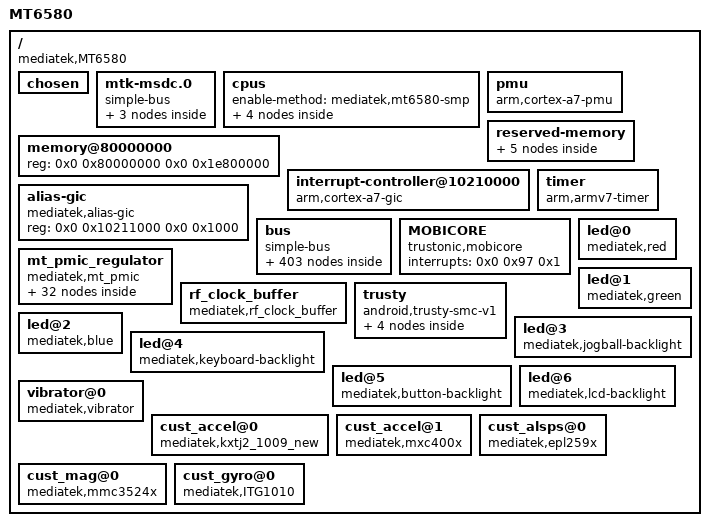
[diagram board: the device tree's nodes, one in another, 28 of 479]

/dts-v1/;

/ {
	model = "MT6580";
	compatible = "mediatek,MT6580";
	interrupt-parent = <0x1>;
	#address-cells = <0x2>;
	#size-cells = <0x2>;

	chosen {
		bootargs = "console=tty0 console=ttyMT0,921600n1 root=/dev/ram initrd=0x84000000,0x400000 loglevel=8";
		atag,videolfb-fb_base = <0x9e800000>;
		atag,videolfb-islcmfound = <0x1>;
		atag,videolfb-fps = <0x1770>;
		atag,videolfb-vramSize = <0x1800000>;
		atag,videolfb-lcmname = "nt35590_AUO";
	};

	mtk-msdc.0 {
		compatible = "simple-bus";
		#address-cells = <0x1>;
		#size-cells = <0x1>;
		ranges = <0x0 0x0 0x0 0xffffffff>;

		msdc0@11120000 {
			compatible = "mediatek,mt6580-mmc";
			reg = <0x11120000 0x10000 0x10001e84 0x2>;
			interrupts = <0x0 0x26 0x8>;
			status = "okay";
			clk_src = [07];
			bus-width = <0x8>;
			max-frequency = <0xc65d400>;
			cap-mmc-highspeed;
			msdc-sys-suspend;
			mmc-hs200-1_8v;
			non-removable;
			pinctl = <0x2>;
			register_setting = <0x3>;
			host_function = [00];
			bootable;
		};

		msdc1@11130000 {
			compatible = "mediatek,mt6580-mmc";
			reg = <0x11130000 0x10000 0x10001e84 0x2>;
			interrupts = <0x0 0x27 0x8>;
			cd-gpios = <0x4 0x3 0x0>;
			status = "okay";
			clk_src = [02];
			bus-width = <0x4>;
			max-frequency = <0xc65d400>;
			msdc-sys-suspend;
			cap-sd-highspeed;
			sd-uhs-sdr12;
			sd-uhs-sdr25;
			sd-uhs-sdr50;
			sd-uhs-sdr104;
			pinctrl-names = "default", "insert_cfg";
			pinctrl-0 = <0x5>;
			pinctrl-1 = <0x6>;
			pinctl = <0x7>;
			pinctl_sdr104 = <0x8>;
			pinctl_sdr50 = <0x9>;
			pinctl_ddr50 = <0xa>;
			register_setting = <0xb>;
			host_function = [01];
			cd_level = [00];
			non-removable;
		};

		default {
			compatible = "mediatek,msdc1_ins-eint";
		};
	};

	cpus {
		#address-cells = <0x1>;
		#size-cells = <0x0>;
		enable-method = "mediatek,mt6580-smp";

		cpu@0 {
			device_type = "cpu";
			compatible = "arm,cortex-a7";
			reg = <0x0>;
			clock-frequency = <0x6553f100>;
		};

		cpu@1 {
			device_type = "cpu";
			compatible = "arm,cortex-a7";
			reg = <0x1>;
			clock-frequency = <0x6553f100>;
		};

		cpu@2 {
			device_type = "cpu";
			compatible = "arm,cortex-a7";
			reg = <0x2>;
			clock-frequency = <0x6553f100>;
		};

		cpu@3 {
			device_type = "cpu";
			compatible = "arm,cortex-a7";
			reg = <0x3>;
			clock-frequency = <0x6553f100>;
		};
	};

	pmu {
		compatible = "arm,cortex-a7-pmu";
		interrupts = <0x0 0x4 0x8 0x0 0x5 0x8 0x0 0x6 0x8 0x0 0x7 0x8>;
	};

	memory@80000000 {
		device_type = "memory";
		reg = <0x0 0x80000000 0x0 0x1e800000>;
	};

	reserved-memory {
		#address-cells = <0x2>;
		#size-cells = <0x2>;
		ranges;

		consys-reserve-memory {
			compatible = "mediatek,consys-reserve-memory";
			no-map;
			size = <0x0 0x200000>;
			alignment = <0x0 0x200000>;
		};

		reserve-memory-ccci_md1 {
			compatible = "mediatek,reserve-memory-ccci_md1";
			no-map;
			size = <0x0 0x1800000>;
			alignment = <0x0 0x2000000>;
			alloc-ranges = <0x0 0x80000000 0x0 0x80000000>;
		};

		pstore-reserved-memory@83f10000 {
			compatible = "mediatek,pstore";
			reg = <0x0 0x83f10000 0x0 0xe0000>;
		};

		ram_console-reserved-memory@83f00000 {
			compatible = "mediatek,ram_console";
			reg = <0x0 0x83f00000 0x0 0x10000>;
		};

		minirdump-reserved-memory@83ff0000 {
			compatible = "mediatek, minirdump";
			reg = <0x0 0x83ff0000 0x0 0x10000>;
		};
	};

	interrupt-controller@10210000 {
		compatible = "arm,cortex-a7-gic";
		#interrupt-cells = <0x3>;
		#address-cells = <0x0>;
		interrupt-controller;
		reg = <0x0 0x10211000 0x0 0x1000 0x0 0x10212000 0x0 0x1000 0x0 0x10200100 0x0 0x1000>;
		interrupts = <0x1 0x9 0xf04>;
		linux,phandle = <0x1>;
		phandle = <0x1>;
	};

	alias-gic {
		compatible = "mediatek,alias-gic";
		reg = <0x0 0x10211000 0x0 0x1000>;
	};

	timer {
		compatible = "arm,armv7-timer";
		interrupts = <0x1 0xd 0x8 0x1 0xe 0x8 0x1 0xb 0x8 0x1 0xa 0x8>;
		clock-frequency = <0xc65d40>;
	};

	bus {
		compatible = "simple-bus";
		#address-cells = <0x1>;
		#size-cells = <0x1>;
		ranges = <0x0 0x0 0x0 0xffffffff>;

		chipid@08000000 {
			compatible = "mediatek,chipid";
			reg = <0x8000000 0x4 0x8000004 0x4 0x8000008 0x4 0x800000c 0x4>;
		};

		TOPCKGEN@0x10000000 {
			compatible = "mediatek,TOPCKGEN";
			reg = <0x10000000 0x1000>;
		};

		INFRACFG_AO@0x10001000 {
			compatible = "mediatek,INFRACFG_AO";
			reg = <0x10001000 0x1000>;
		};

		bat_meter {
			compatible = "mediatek,bat_meter";
			r_bat_sense = <0x4>;
			r_i_sense = <0x4>;
			r_charger_1 = <0x14a>;
			r_charger_2 = <0x27>;
			temperature_t0 = <0x6e>;
			temperature_t1 = <0x0>;
			temperature_t2 = <0x19>;
			temperature_t3 = <0x32>;
			temperature_t = <0xff>;
			fg_meter_resistance = <0x0>;
			q_max_pos_50 = <0xc5d>;
			q_max_pos_25 = <0xc06>;
			q_max_pos_0 = <0xa97>;
			q_max_neg_10 = <0x9de>;
			q_max_pos_50_h_current = <0xc4d>;
			q_max_pos_25_h_current = <0xc07>;
			q_max_pos_0_h_current = <0xa4b>;
			q_max_neg_10_h_current = <0x679>;
			oam_d5 = <0x0>;
			change_tracking_point = <0x1>;
			cust_tracking_point = <0x1>;
			cust_r_sense = <0xdc>;
			cust_hw_cc = <0x0>;
			aging_tuning_value = <0x67>;
			cust_r_fg_offset = <0x0>;
			ocv_board_compesate = <0x0>;
			r_fg_board_base = <0x3e8>;
			r_fg_board_slope = <0x3e8>;
			car_tune_value = <0x64>;
			current_detect_r_fg = <0xa>;
			minerroroffset = <0x3e8>;
			fg_vbat_average_size = <0x12>;
			r_fg_value = <0xa>;
			cust_poweron_delta_capacity_tolrance = <0x1e>;
			cust_poweron_low_capacity_tolrance = <0x5>;
			cust_poweron_max_vbat_tolrance = <0x5a>;
			cust_poweron_delta_vbat_tolrance = <0x1e>;
			cust_poweron_delta_hw_sw_ocv_capacity_tolrance = <0xa>;
			fixed_tbat_25 = <0x0>;
			vbat_normal_wakeup = <0xe10>;
			vbat_low_power_wakeup = <0xdac>;
			normal_wakeup_period = <0x1518>;
			low_power_wakeup_period = <0x12c>;
			close_poweroff_wakeup_period = <0x1e>;
			rbat_pull_up_r = <0x4204>;
			rbat_pull_up_volt = <0x708>;
			batt_temperature_table_num = <0x11>;
			batt_temperature_table = <0xffffffec 0x10a8d 0xfffffff1 0xd192 0xfffffff6 0xa60a 0xfffffffb 0x8464 0x0 0x6a53 0x5 0x5605 0xa 0x4606 0xf 0x3952 0x14 0x2f31 0x19 0x2710 0x1e 0x207b 0x23 0x1b24 0x28 0x16ca 0x2d 0x1335 0x32 0x1041 0x37 0xdcf 0x3c 0xbc6>;
			battery_profile_t0_num = <0x40>;
			battery_profile_t0 = <0x0 0x10ef 0x2 0x10d9 0x4 0x10c5 0x6 0x10b0 0x8 0x109f 0xa 0x108c 0xc 0x107a 0xe 0x1068 0x10 0x105a 0x12 0x1050 0x14 0x1040 0x16 0x1021 0x18 0x1000 0x1a 0xfe3 0x1c 0xfc1 0x1e 0xf8b 0x20 0xf72 0x22 0xf5f 0x24 0xf4e 0x26 0xf41 0x28 0xf35 0x2a 0xf28 0x2c 0xf1e 0x2e 0xf15 0x30 0xf0d 0x31 0xf04 0x33 0xefb 0x35 0xef4 0x37 0xeec 0x39 0xee2 0x3b 0xedc 0x3d 0xed4 0x3f 0xecd 0x41 0xec6 0x43 0xec0 0x45 0xebb 0x47 0xeb6 0x49 0xeb0 0x4b 0xeab 0x4d 0xea4 0x4f 0xe9d 0x51 0xe96 0x53 0xe8f 0x55 0xe86 0x57 0xe7c 0x59 0xe72 0x5b 0xe64 0x5d 0xe4c 0x5f 0xe28 0x61 0xdee 0x63 0xd81 0x64 0xd48 0x64 0xd48 0x64 0xd48 0x64 0xd48 0x64 0xd48 0x64 0xd48 0x64 0xd48 0x64 0xd48 0x64 0xd48 0x64 0xd48 0x64 0xd48 0x64 0xd48 0x64 0xd48>;
			battery_profile_t1_num = <0x40>;
			battery_profile_t1 = <0x0 0x10e9 0x2 0x10cf 0x4 0x10b8 0x6 0x10a4 0x7 0x1091 0x9 0x107f 0xb 0x106d 0xd 0x105a 0xf 0x104a 0x11 0x1038 0x12 0x1027 0x14 0x1016 0x16 0x1006 0x18 0xffa 0x1a 0xfec 0x1c 0xfd5 0x1e 0xfb7 0x1f 0xf9c 0x21 0xf87 0x23 0xf77 0x25 0xf6b 0x27 0xf5e 0x29 0xf51 0x2a 0xf46 0x2c 0xf3c 0x2e 0xf31 0x30 0xf28 0x32 0xf1e 0x34 0xf15 0x35 0xf0c 0x37 0xf05 0x39 0xefd 0x3b 0xef7 0x3d 0xef0 0x3f 0xee8 0x41 0xee1 0x42 0xedb 0x44 0xed4 0x46 0xecd 0x48 0xec6 0x4a 0xebf 0x4c 0xeb8 0x4d 0xeaf 0x4f 0xea7 0x51 0xe9c 0x53 0xe92 0x55 0xe89 0x57 0xe84 0x59 0xe80 0x5a 0xe7d 0x5c 0xe77 0x5e 0xe67 0x60 0xe3d 0x62 0xdf1 0x64 0xd48 0x64 0xd48 0x64 0xd48 0x64 0xd48 0x64 0xd48 0x64 0xd48 0x64 0xd48 0x64 0xd48 0x64 0xd48 0x64 0xd48>;
			battery_profile_t2_num = <0x40>;
			battery_profile_t2 = <0x0 0x10fe 0x2 0x10e9 0x3 0x10d5 0x5 0x10c3 0x6 0x10b1 0x8 0x109e 0xa 0x108c 0xb 0x107a 0xd 0x1069 0xf 0x1057 0x10 0x1046 0x12 0x1035 0x13 0x1024 0x15 0x1013 0x17 0x1003 0x18 0xff5 0x1a 0xfeb 0x1c 0xfd9 0x1d 0xfc4 0x1f 0xfb0 0x20 0xfa4 0x22 0xf99 0x24 0xf8f 0x25 0xf83 0x27 0xf77 0x29 0xf66 0x2a 0xf51 0x2c 0xf3e 0x2d 0xf31 0x2f 0xf26 0x31 0xf1c 0x32 0xf14 0x34 0xf0c 0x36 0xf04 0x37 0xefd 0x39 0xef6 0x3a 0xeef 0x3c 0xee9 0x3e 0xee4 0x3f 0xedf 0x41 0xedb 0x43 0xed7 0x44 0xed2 0x46 0xecd 0x47 0xec8 0x49 0xec3 0x4b 0xebd 0x4c 0xeb7 0x4e 0xeb0 0x50 0xeaa 0x51 0xea5 0x53 0xe9d 0x54 0xe92 0x56 0xe89 0x58 0xe79 0x59 0xe74 0x5b 0xe71 0x5d 0xe70 0x5e 0xe6d 0x60 0xe65 0x61 0xe34 0x63 0xdda 0x64 0xd48 0x64 0xd48>;
			battery_profile_t3_num = <0x40>;
			battery_profile_t3 = <0x0 0x1101 0x2 0x10ed 0x3 0x10dc 0x5 0x10c8 0x6 0x10b5 0x8 0x10a3 0x9 0x1092 0xb 0x107f 0xd 0x106d 0xe 0x105c 0x10 0x104a 0x11 0x1038 0x13 0x1028 0x15 0x1017 0x16 0x1008 0x18 0xff9 0x19 0xfe9 0x1b 0xfd9 0x1c 0xfcb 0x1e 0xfbc 0x20 0xfad 0x21 0xfa1 0x23 0xf94 0x24 0xf88 0x26 0xf7c 0x27 0xf71 0x29 0xf64 0x2b 0xf58 0x2c 0xf43 0x2e 0xf2f 0x2f 0xf22 0x31 0xf18 0x33 0xf0f 0x34 0xf07 0x36 0xeff 0x37 0xef8 0x39 0xef0 0x3a 0xeeb 0x3c 0xee4 0x3e 0xedf 0x3f 0xeda 0x41 0xed5 0x42 0xed1 0x44 0xecd 0x46 0xec8 0x47 0xec3 0x49 0xeb8 0x4a 0xeb0 0x4c 0xeab 0x4d 0xea2 0x4f 0xe9d 0x51 0xe97 0x52 0xe91 0x54 0xe89 0x55 0xe7d 0x57 0xe72 0x58 0xe65 0x5a 0xe61 0x5c 0xe61 0x5d 0xe5f 0x5f 0xe59 0x60 0xe38 0x62 0xdeb 0x64 0xd48>;
			r_profile_t0_num = <0x40>;
			r_profile_t0 = <0x10c 0x10ef 0x138 0x10d9 0x141 0x10c5 0x144 0x10b0 0x151 0x109f 0x14f 0x108c 0x159 0x107a 0x15a 0x1068 0x161 0x105a 0x176 0x1050 0x189 0x1040 0x187 0x1021 0x19b 0x1000 0x1c9 0xfe3 0x247 0xfc1 0x37b 0xf8b 0x3a8 0xf72 0x3a3 0xf5f 0x39b 0xf4e 0x39a 0xf41 0x397 0xf35 0x393 0xf28 0x397 0xf1e 0x398 0xf15 0x39c 0xf0d 0x3a0 0xf04 0x39f 0xefb 0x3a6 0xef4 0x3ab 0xeec 0x3a7 0xee2 0x3af 0xedc 0x3af 0xed4 0x3b7 0xecd 0x3b8 0xec6 0x3bc 0xec0 0x3bf 0xebb 0x3c6 0xeb6 0x3d1 0xeb0 0x3d9 0xeab 0x3e6 0xea4 0x3f2 0xe9d 0x405 0xe96 0x41a 0xe8f 0x42e 0xe86 0x449 0xe7c 0x46d 0xe72 0x48f 0xe64 0x4c0 0xe4c 0x4f8 0xe28 0x54c 0xdee 0x5db 0xd81 0x5db 0xd48 0x5db 0xd48 0x5db 0xd48 0x5db 0xd48 0x5db 0xd48 0x5db 0xd48 0x5db 0xd48 0x5db 0xd48 0x5db 0xd48 0x5db 0xd48 0x5db 0xd48 0x5db 0xd48 0x5db 0xd48>;
			r_profile_t1_num = <0x40>;
			r_profile_t1 = <0xe1 0x10e9 0x17c 0x10cf 0x180 0x10b8 0x182 0x10a4 0x184 0x1091 0x188 0x107f 0x18a 0x106d 0x189 0x105a 0x18f 0x104a 0x190 0x1038 0x196 0x1027 0x195 0x1016 0x195 0x1006 0x19c 0xffa 0x1a3 0xfec 0x19c 0xfd5 0x198 0xfb7 0x192 0xf9c 0x186 0xf87 0x183 0xf77 0x183 0xf6b 0x17b 0xf5e 0x173 0xf51 0x173 0xf46 0x176 0xf3c 0x173 0xf31 0x176 0xf28 0x174 0xf1e 0x176 0xf15 0x176 0xf0c 0x17b 0xf05 0x17b 0xefd 0x181 0xef7 0x182 0xef0 0x180 0xee8 0x182 0xee1 0x18a 0xedb 0x184 0xed4 0x186 0xecd 0x188 0xec6 0x184 0xebf 0x184 0xeb8 0x17f 0xeaf 0x181 0xea7 0x181 0xe9c 0x17c 0xe92 0x179 0xe89 0x17d 0xe84 0x185 0xe80 0x196 0xe7d 0x1b0 0xe77 0x1c6 0xe67 0x1d0 0xe3d 0x1e6 0xdf1 0x1e6 0xd48 0x1e6 0xd48 0x1e6 0xd48 0x1e6 0xd48 0x1e6 0xd48 0x1e6 0xd48 0x1e6 0xd48 0x1e6 0xd48 0x1e6 0xd48 0x1e6 0xd48>;
			r_profile_t2_num = <0x40>;
			r_profile_t2 = <0x8a 0x10fe 0x57 0x10e9 0x58 0x10d5 0x5c 0x10c3 0x5c 0x10b1 0x5c 0x109e 0x5d 0x108c 0x5e 0x107a 0x63 0x1069 0x65 0x1057 0x66 0x1046 0x66 0x1035 0x66 0x1024 0x65 0x1013 0x6a 0x1003 0x69 0xff5 0x70 0xfeb 0x6e 0xfd9 0x71 0xfc4 0x72 0xfb0 0x7b 0xfa4 0x7e 0xf99 0x81 0xf8f 0x86 0xf83 0x85 0xf77 0x7e 0xf66 0x70 0xf51 0x64 0xf3e 0x5d 0xf31 0x5e 0xf26 0x5f 0xf1c 0x5f 0xf14 0x5f 0xf0c 0x5e 0xf04 0x5e 0xefd 0x5c 0xef6 0x5c 0xeef 0x5e 0xee9 0x5b 0xee4 0x5f 0xedf 0x62 0xedb 0x65 0xed7 0x63 0xed2 0x62 0xecd 0x62 0xec8 0x5e 0xec3 0x5d 0xebd 0x5e 0xeb7 0x5b 0xeb0 0x5b 0xeaa 0x60 0xea5 0x5e 0xe9d 0x60 0xe92 0x64 0xe89 0x5b 0xe79 0x5b 0xe74 0x5f 0xe71 0x66 0xe70 0x6e 0xe6d 0x79 0xe65 0x6e 0xe34 0x7a 0xdda 0x7a 0xd48 0x7a 0xd48>;
			r_profile_t3_num = <0x40>;
			r_profile_t3 = <0x6e 0x1101 0x35 0x10ed 0x3a 0x10dc 0x38 0x10c8 0x39 0x10b5 0x3a 0x10a3 0x3c 0x1092 0x3b 0x107f 0x39 0x106d 0x3d 0x105c 0x3b 0x104a 0x3a 0x1038 0x3b 0x1028 0x3a 0x1017 0x3e 0x1008 0x3e 0xff9 0x3d 0xfe9 0x3c 0xfd9 0x43 0xfcb 0x43 0xfbc 0x40 0xfad 0x42 0xfa1 0x45 0xf94 0x49 0xf88 0x4d 0xf7c 0x50 0xf71 0x55 0xf64 0x57 0xf58 0x4b 0xf43 0x3f 0xf2f 0x3e 0xf22 0x3c 0xf18 0x3e 0xf0f 0x3b 0xf07 0x40 0xeff 0x3b 0xef8 0x38 0xef0 0x40 0xeeb 0x3d 0xee4 0x40 0xedf 0x41 0xeda 0x40 0xed5 0x44 0xed1 0x44 0xecd 0x46 0xec8 0x48 0xec3 0x3f 0xeb8 0x3f 0xeb0 0x41 0xeab 0x3e 0xea2 0x41 0xe9d 0x3f 0xe97 0x40 0xe91 0x41 0xe89 0x41 0xe7d 0x41 0xe72 0x3c 0xe65 0x3b 0xe61 0x41 0xe61 0x45 0xe5f 0x4d 0xe59 0x47 0xe38 0x51 0xdeb 0x51 0xd48>;
		};

		BAT_NOTIFY {
			compatible = "mediatek,bat_notify";
		};

		bat_comm {
			compatible = "mediatek,battery";
			stop_charging_in_takling = <0x1>;
			talking_recharge_voltage = <0xed8>;
			talking_sync_time = <0x3c>;
			mtk_temperature_recharge_support = <0x1>;
			max_charge_temperature = <0x32>;
			max_charge_temperature_minus_x_degree = <0x2f>;
			min_charge_temperature = <0x0>;
			min_charge_temperature_plus_x_degree = <0x6>;
			err_charge_temperature = <0xff>;
			v_pre2cc_thres = <0xd48>;
			v_cc2topoff_thres = <0x10cc>;
			recharging_voltage = <0x10a4>;
			charging_full_current = <0xb4>;
			config_usb_if = <0x0>;
			usb_charger_current_suspend = <0x0>;
			usb_charger_current_unconfigured = <0x1b58>;
			usb_charger_current_configured = <0xc350>;
			usb_charger_current = <0xc350>;
			ac_charger_current = <0x1adb0>;
			non_std_ac_charger_current = <0xc350>;
			charging_host_charger_current = <0xfde8>;
			apple_0_5a_charger_current = <0xc350>;
			apple_1_0a_charger_current = <0xfde8>;
			apple_2_1a_charger_current = <0x13880>;
			bat_low_temp_protect_enable = <0x0>;
			v_charger_enable = <0x0>;
			v_charger_max = <0x1964>;
			v_charger_min = <0x1130>;
			onehundred_percent_tracking_time = <0xa>;
			npercent_tracking_time = <0x14>;
			sync_to_real_tracking_time = <0x3c>;
			v_0percent_tracking = <0xd7a>;
			high_battery_voltage_support = <0x1>;
		};

		keypad@10002000 {
			compatible = "mediatek,mt6580-keypad";
			reg = <0x10002000 0x1000>;
			interrupts = <0x0 0x6d 0x2>;
			mediatek,kpd-key-debounce = <0x400>;
			mediatek,kpd-sw-pwrkey = <0x74>;
			mediatek,kpd-hw-pwrkey = <0x8>;
			mediatek,kpd-sw-rstkey = <0x66>;
			mediatek,kpd-hw-rstkey = <0x11>;
			mediatek,kpd-use-extend-type = <0x0>;
			mediatek,kpd-hw-map-num = <0x48>;
            mediatek,kpd-hw-init-map = <115 114 0 0 0 0 0 0 0 0 
			                    	0 0 0 0 0 0 0 0 0 
					    	    	0 0 0 0 0 0 0 0 0 
							   		0 0 0 0 0 0 0 0 0 
						   			0 0 0 0 0 0 0 0 0 
						   			0 0 0 0 0 0 0 0 0 
							   		0 0 0 0 0 0 0 0 0 
							   		0 0 0 0 0 0 0 0 >;	
			mediatek,kpd-pwrkey-eint-gpio = <0x0>;
			mediatek,kpd-pwkey-gpio-din = <0x0>;
			mediatek,kpd-hw-dl-key0 = <0x0>;
			mediatek,kpd-hw-dl-key1 = <0x1>;
			mediatek,kpd-hw-dl-key2 = <0x8>;
			mediatek,kpd-hw-recovery-key = <0>;
			mediatek,kpd-hw-factory-key = <1>;
			status = "okay";
		};

		PERICFG@0x10003000 {
			compatible = "mediatek,PERICFG";
			reg = <0x10003000 0x1000>;
		};

		RESERVED@0x10004000 {
			compatible = "mediatek,RESERVED";
			reg = <0x10004000 0x1000>;
		};

		gpio {
			compatible = "mediatek,gpio_usage_mapping";
			GPIO_SIM1_SCLK = <0x16>;
			GPIO_SIM1_SIO = <0x17>;
			GPIO_SIM2_SIO = <0x18>;
			GPIO_SIM2_SCLK = <0x19>;
		};

		gpio@0x10005000 {
			compatible = "mediatek,gpio";
			reg = <0x10005000 0x1000>;
		};

		SLEEP@0x10006000 {
			compatible = "mediatek,SLEEP";
			reg = <0x10006000 0x1000>;
			interrupts = <0x0 0x58 0x8 0x0 0x59 0x8 0x0 0x5a 0x8 0x0 0x5b 0x8>;
		};

		TOPRGU@0x10007000 {
			compatible = "mediatek,TOPRGU";
			reg = <0x10007000 0x1000>;
			interrupts = <0x0 0x9d 0x2>;
		};

		APXGPT@0x10008000 {
			compatible = "mediatek,APXGPT";
			reg = <0x10008000 0x1000>;
			interrupts = <0x0 0x5c 0x8>;
			clock-frequency = <0xc65d40>;
		};

		EFUSEC@0x10009000 {
			compatible = "mediatek,EFUSEC";
			reg = <0x10009000 0x1000>;
		};

		hacc@0x1000A000 {
			compatible = "mediatek,hacc";
			reg = <0x1000a000 0x1000>;
			interrupts = <0x0 0x6e 0x0>;
		};

		cpu_dbgapb@10170000 {
			compatible = "mediatek,hw_dbg";
			num = <0x4>;
			reg = <0x10170000 0x2000 0x10172000 0x2000 0x10174000 0x2000 0x10176000 0x2000>;
		};

		eintc@1000b000 {
			compatible = "mediatek,mt-eic";
			reg = <0x1000b000 0x1000>;
			interrupts = <0x0 0x5e 0x4>;
			#interrupt-cells = <0x2>;
			interrupt-controller;
			mediatek,max_eint_num = <0x1a>;
			mediatek,mapping_table_entry = <0x53>;
			mediatek,mapping_table = <0x0 0x0 0x1 0x1 0x2 0x2 0x3 0x3 0x4 0x4 0x5 0x5 0x6 0x6 0x7 0x7 0x8 0x8 0x9 0x9 0xa 0xa 0xb 0xb 0xc 0xc 0xd 0xd 0xe 0xe 0xf 0xf 0x10 0x0 0x11 0x1 0x12 0x2 0x13 0x3 0x14 0x4 0x15 0x5 0x16 0x6 0x17 0x7 0x18 0x8 0x19 0x9 0x1a 0xa 0x1b 0xb 0x1c 0xc 0x1d 0xd 0x1e 0xe 0x1f 0xf 0x20 0x0 0x21 0x1 0x22 0x2 0x23 0x3 0x24 0x4 0x25 0x5 0x26 0x6 0x27 0x7 0x28 0x8 0x29 0x9 0x2a 0xa 0x2b 0xb 0x2c 0xc 0x2d 0xd 0x2e 0xe 0x2f 0xf 0x30 0x0 0x31 0x1 0x32 0x2 0x33 0x3 0x34 0x3 0x35 0x4 0x36 0x5 0x37 0x6 0x38 0x7 0x39 0x8 0x3a 0xa 0x3b 0xb 0x3c 0xc 0x3d 0xd 0x3e 0xe 0x3f 0xf 0x40 0x0 0x41 0x1 0x42 0x2 0x43 0x3 0x44 0x10 0x45 0x4 0x46 0x5 0x47 0x6 0x48 0x7 0x49 0x8 0x4a 0x9 0x4b 0xa 0x4c 0xb 0x4d 0xc 0x4e 0xd 0x51 0x0 0x52 0x1 0x53 0x2 0x54 0x3>;
			mediatek,builtin_entry = <0xb>;
			mediatek,builtin_mapping = <0x0 0x3 0x14 0x1 0x3 0x12 0x7 0x4 0x14 0x8 0x4 0x12 0x9 0x3 0x14 0xa 0x3 0x12 0x18 0x5 0x14 0x19 0x5 0x12 0x4d 0x2 0x14 0x4e 0x2 0x12 0xd 0x1 0x11>;
			linux,phandle = <0xc>;
			phandle = <0xc>;

			pmic@13 {
				compatible = "mediatek, pmic-eint";
				interrupt-parent = <0xc>;
				interrupts = <0xd 0x4>;
				debounce = <0xd 0x3e8>;
			};
		};

		ap_ccif0@1000C000 {
			compatible = "mediatek,ap_ccif0";
			reg = <0x1000c000 0x1000 0x1000d000 0x1000>;
			interrupts = <0x0 0x5d 0x8 0x0 0x98 0x2>;
			mediatek,ccif_capability = <0x2>;
			mediatek,md_smem_size = <0x200000>;
		};

		MCUSYS_CFGREG@0x1020000 {
			compatible = "mediatek,MCUSYS_CFGREG_BASE";
			reg = <0x1020000 0x200>;
		};

		mcucfg@10200000 {
			compatible = "mediatek,mt6580-mcucfg";
			reg = <0x10200000 0x200>;
		};

		AES@0x1000E000 {
			compatible = "mediatek,AES";
			reg = <0x1000e000 0x1000>;
		};

		PWRAP@0x1000F000 {
			compatible = "mediatek,PWRAP";
			reg = <0x1000f000 0x1000>;
			interrupts = <0x0 0x6c 0x0>;
		};

		DEVAPC_AO@0x10010000 {
			compatible = "mediatek,DEVAPC_AO";
			reg = <0x10010000 0x1000>;
		};

		MIPI_CONFG@0x10011000 {
			compatible = "mediatek,MIPI_CONFG";
			reg = <0x10011000 0x1000>;
		};

		INFRA_MBIST@0x10012000 {
			compatible = "mediatek,INFRA_MBIST";
			reg = <0x10012000 0x1000>;
		};

		RESERVED@0x10013000 {
			compatible = "mediatek,RESERVED";
			reg = <0x10013000 0x1000>;
		};

		IOCFG_T@0x10014000 {
			compatible = "mediatek,IOCFG_T";
			reg = <0x10014000 0x1000>;
		};

		IOCFG_B@0x10015000 {
			compatible = "mediatek,IOCFG_B";
			reg = <0x10015000 0x1000>;
		};

		IOCFG_L@0x10016000 {
			compatible = "mediatek,IOCFG_L";
			reg = <0x10016000 0x1000>;
		};

		IOCFG_R@0x10017000 {
			compatible = "mediatek,IOCFG_R";
			reg = <0x10017000 0x1000>;
		};

		APMIXED@0x10018000 {
			compatible = "mediatek,APMIXED";
			reg = <0x10018000 0x1000>;
		};

		MCUCFG@0x10200000 {
			compatible = "mediatek,MCUCFG";
			reg = <0x10200000 0x1000>;
		};

		INFRACFG@0x10201000 {
			compatible = "mediatek,INFRACFG";
			reg = <0x10201000 0x1000>;
		};

		sys_cirq@10202000 {
			compatible = "mediatek,mt6580-sys_cirq", "mediatek,mt6735-sys_cirq";
			reg = <0x10202000 0x1000>;
			interrupts = <0x0 0x9e 0x8>;
			mediatek,cirq_num = <0x7e>;
			mediatek,spi_start_offset = <0x20>;
		};

		m4u@10203000 {
			cell-index = <0x0>;
			compatible = "mediatek,m4u";
			reg = <0x10203000 0x1000>;
			interrupts = <0x0 0x51 0x8>;
		};

		DEVAPC@0x10204000 {
			compatible = "mediatek,DEVAPC";
			reg = <0x10204000 0x1000>;
			interrupts = <0x0 0x4a 0x8>;
		};

		EMI@0x10205000 {
			compatible = "mediatek,EMI";
			reg = <0x10205000 0x1000>;
			interrupts = <0x0 0x4c 0x4>;
		};

		DRAMC_NAO@0x10206000 {
			compatible = "mediatek,DRAMC_NAO";
			reg = <0x10206000 0x1000>;
		};

		DRAMC0@0x10207000 {
			compatible = "mediatek,DRAMC0";
			reg = <0x10207000 0x1000>;
		};

		DDRPHY@0x10208000 {
			compatible = "mediatek,DDRPHY";
			reg = <0x10208000 0x1000>;
		};

		SRAMROM@0x10209000 {
			compatible = "mediatek,SRAMROM";
			reg = <0x10209000 0x1000>;
		};

		gce@1020a000 {
			compatible = "mediatek,gce";
			reg = <0x1020a000 0x1000>;
			interrupts = <0x0 0x55 0x8 0x0 0x56 0x8>;
			disp_mutex_reg = <0x14015000 0x1000>;
			g3d_config_base = <0x13000000 0x0 0xffff0000>;
			mmsys_config_base = <0x14000000 0x1 0xffff0000>;
			disp_dither_base = <0x14010000 0x2 0xffff0000>;
			mm_na_base = <0x14020000 0x3 0xffff0000>;
			imgsys_base = <0x15000000 0x4 0xffff0000>;
			vdec_gcon_base = <0x16000000 0x5 0xffff0000>;
			venc_gcon_base = <0x17000000 0x6 0xffff0000>;
			conn_peri_base = <0x18000000 0x7 0xffff0000>;
			topckgen_base = <0x10000000 0x8 0xffff0000>;
			kp_base = <0x10010000 0x9 0xffff0000>;
			scp_sram_base = <0x10020000 0xa 0xffff0000>;
			infra_na3_base = <0x10030000 0xb 0xffff0000>;
			infra_na4_base = <0x10040000 0xc 0xffff0000>;
			scp_base = <0x10050000 0xd 0xffff0000>;
			mcucfg_base = <0x10200000 0xe 0xffff0000>;
			gcpu_base = <0x10210000 0xf 0xffff0000>;
			usb0_base = <0x11200000 0x10 0xffff0000>;
			usb_sif_base = <0x11210000 0x11 0xffff0000>;
			audio_base = <0x11220000 0x12 0xffff0000>;
			msdc0_base = <0x11230000 0x13 0xffff0000>;
			msdc1_base = <0x11240000 0x14 0xffff0000>;
			msdc2_base = <0x11250000 0x15 0xffff0000>;
			msdc3_base = <0x11260000 0x16 0xffff0000>;
			pwm_sw_base = <0x1100f000 0x63 0xfffff000>;
			mdp_rdma0_sof = <0x0>;
			mdp_rsz0_sof = <0x1>;
			mdp_rsz1_sof = <0x2>;
			mdp_tdshp_sof = <0x3>;
			mdp_wdma_sof = <0x4>;
			mdp_wrot_sof = <0x5>;
			disp_ovl0_sof = <0x6>;
			disp_rdma0_sof = <0x8>;
			disp_wdma0_sof = <0xa>;
			disp_color_sof = <0xc>;
			disp_aal_sof = <0xd>;
			disp_gamma_sof = <0xe>;
			disp_dither_sof = <0xf>;
			disp_pwm0_sof = <0x11>;
			mdp_rdma0_frame_done = <0x12>;
			mdp_rsz0_frame_done = <0x13>;
			mdp_rsz1_frame_done = <0x14>;
			mdp_tdshp_frame_done = <0x15>;
			mdp_wdma_frame_done = <0x16>;
			mdp_wrot_write_frame_done = <0x17>;
			mdp_wrot_read_frame_done = <0x18>;
			disp_ovl0_frame_done = <0x19>;
			disp_rdma0_frame_done = <0x1b>;
			disp_wdma0_frame_done = <0x1d>;
			disp_color_frame_done = <0x1f>;
			disp_aal_frame_done = <0x20>;
			disp_gamma_frame_done = <0x21>;
			disp_dither_frame_done = <0x22>;
			disp_dsi0_frame_done = <0x25>;
			stream_done_0 = <0x26>;
			stream_done_1 = <0x27>;
			stream_done_2 = <0x28>;
			stream_done_3 = <0x29>;
			stream_done_4 = <0x2a>;
			stream_done_5 = <0x2b>;
			stream_done_6 = <0x2c>;
			stream_done_7 = <0x2d>;
			stream_done_8 = <0x2e>;
			stream_done_9 = <0x2f>;
			buf_underrun_event_0 = <0x30>;
			dsi0_te_event = <0x32>;
			isp_frame_done_p2_1 = <0x42>;
			isp_frame_done_p2_0 = <0x43>;
			seninf_cam0_fifo_full = <0x49>;
			apxgpt2_count = <0x10008028>;
		};

		bus_dbg@1020b000 {
			compatible = "mediatek,bus_dbg-v2";
			reg = <0x1020b000 0x1000>;
			interrupts = <0x0 0x49 0x8>;
			two_stage_timeout = <0x1>;
		};

		TRNG@0x1020C000 {
			compatible = "mediatek,TRNG";
			reg = <0x1020c000 0x1000>;
			interrupts = <0x0 0x57 0x8>;
		};

		MCUCFG_BIU@0x1020D000 {
			compatible = "mediatek,MCUCFG_BIU";
			reg = <0x1020d000 0x1000>;
		};

		DBGSYS_DEM@0x1011A000 {
			compatible = "mediatek,DBGSYS_DEM";
			reg = <0x1011a000 0x1000>;
		};

		DBGSYS_CTI@0x10112000 {
			compatible = "mediatek,DBGSYS_CTI";
			reg = <0x10112000 0x1000>;
		};

		DBGSYS_DAPROM@0x10110000 {
			compatible = "mediatek,DBGSYS_DAPROM";
			reg = <0x10110000 0x1000>;
		};

		DBGSYS_CPU@0x10160000 {
			compatible = "mediatek,DBGSYS_CPU";
			reg = <0x10160000 0x20000>;
		};

		DBGSYS_MDSYS@0x10120000 {
			compatible = "mediatek,DBGSYS_MDSYS";
			reg = <0x10120000 0x10000>;
		};

		dma@0x11000000 {
			compatible = "mediatek,ap_dma";
			reg = <0x11000000 0x1000>;
			interrupts = <0x0 0x30 0x8>;
		};

		NFI@0x11001000 {
			compatible = "mediatek,NFI";
			reg = <0x11001000 0x1000>;
			interrupts = <0x0 0x2f 0x8>;
		};

		NFIECC@0x11002000 {
			compatible = "mediatek,NFIECC";
			reg = <0x11002000 0x1000>;
			interrupts = <0x0 0x2e 0x8>;
		};

		adc_hw@11003000 {
			compatible = "mediatek,mt6735-auxadc";
			reg = <0x11003000 0x1000>;
			interrupts = <0x0 0x23 0x2>;

			adc_channel@ {
				compatible = "mediatek,adc_channel";
				mediatek,temperature0 = <0x0>;
				mediatek,adc_fdd_rf_params_dynamic_custom_ch = <0x1>;
				mediatek,lcm_voltage = <0xc>;
				status = "okay";
			};
		};

		FHCTL@0x11004000 {
			compatible = "mediatek,FHCTL";
			reg = <0x11004000 0x1000>;
		};

		AP_UART0@0x11005000 {
			cell-index = <0x0>;
			compatible = "mediatek,AP_UART0";
			reg = <0x11005000 0x1000>;
			interrupts = <0x0 0x2c 0x8>;
		};

		AP_UART1@0x11006000 {
			cell-index = <0x1>;
			compatible = "mediatek,AP_UART1";
			reg = <0x11006000 0x1000>;
			interrupts = <0x0 0x2d 0x8>;
		};

		AP_DMA_UART0_TX@0x11000480 {
			compatible = "mediatek,AP_DMA_UART0_TX";
			reg = <0x11000480 0x80>;
			interrupts = <0x0 0x38 0x8>;
		};

		AP_DMA_UART0_RX@0x11000500 {
			compatible = "mediatek,AP_DMA_UART0_RX";
			reg = <0x11000500 0x80>;
			interrupts = <0x0 0x39 0x8>;
		};

		AP_DMA_UART1_TX@0x11000580 {
			compatible = "mediatek,AP_DMA_UART1_TX";
			reg = <0x11000580 0x80>;
			interrupts = <0x0 0x3a 0x8>;
		};

		AP_DMA_UART1_RX@0x11000600 {
			compatible = "mediatek,AP_DMA_UART1_RX";
			reg = <0x11000600 0x80>;
			interrupts = <0x0 0x3b 0x8>;
		};

		PWM@0x11008000 {
			compatible = "mediatek,PWM";
			reg = <0x11008000 0x1000>;
			interrupts = <0x0 0x24 0x8>;
		};

		syscfg_pctl_a@0x10005000 {
			compatible = "mediatek,mt6580-pctl-a-syscfg", "syscon";
			reg = <0x10211000 0x1000>;
			linux,phandle = <0xd>;
			phandle = <0xd>;
		};

		pinctrl@0x10005000 {
			compatible = "mediatek,mt6580-pinctrl";
			reg = <0x10005000 0x1000>;
			mediatek,pctl-regmap = <0xd>;
			pins-are-numbered;
			gpio-controller;
			#gpio-cells = <0x2>;
			linux,phandle = <0x4>;
			phandle = <0x4>;

			mmc0@default {
				linux,phandle = <0x2>;
				phandle = <0x2>;

				pins_cmd {
					drive-strength = [02];
				};

				pins_dat {
					drive-strength = [02];
				};

				pins_clk {
					drive-strength = [02];
				};

				pins_rst {
					drive-strength = [02];
				};

				pins_ds {
					drive-strength = [02];
				};
			};

			mmc0@register_default {
				dat0rddly = [00];
				dat1rddly = [00];
				dat2rddly = [00];
				dat3rddly = [00];
				dat4rddly = [00];
				dat5rddly = [00];
				dat6rddly = [00];
				dat7rddly = [00];
				datwrddly = [00];
				cmdrrddly = [00];
				cmdrddly = [00];
				cmd_edge = [01];
				rdata_edge = [01];
				wdata_edge = [01];
				ett-hs200-cells = <0xc>;
				ett-hs200-default = <0xb0 0x380 0x0 0xb0 0x7c00 0x0 0xb4 0x38 0x1 0x4 0x2 0x1 0xf0 0x1f0000 0x0 0xf0 0x7c00000 0x0 0xb4 0x7 0x1 0xf0 0x1f 0x0 0x4 0x100 0x1 0xf8 0x1f000000 0x0 0xf0 0x1f00 0x0 0xb0 0x8 0x1>;
				linux,phandle = <0x3>;
				phandle = <0x3>;
			};

			mmc1@default {
				linux,phandle = <0x7>;
				phandle = <0x7>;

				pins_cmd {
					drive-strength = [03];
				};

				pins_dat {
					drive-strength = [03];
				};

				pins_clk {
					drive-strength = [03];
				};
			};

			mmc1_ins_default {
				linux,phandle = <0x5>;
				phandle = <0x5>;
			};

			mmc1_ins_cfg {
				linux,phandle = <0x6>;
				phandle = <0x6>;

				pins_insert {
					pins = <0x2200>;
					input-schmitt-enable = <0x1>;
					slew-rate = <0x0>;
					bias-pull-up = <0x0>;
				};
			};

			mmc1@sdr104 {
				linux,phandle = <0x8>;
				phandle = <0x8>;

				pins_cmd {
					drive-strength = [02];
				};

				pins_dat {
					drive-strength = [02];
				};

				pins_clk {
					drive-strength = [03];
				};
			};

			mmc1@sdr50 {
				linux,phandle = <0x9>;
				phandle = <0x9>;

				pins_cmd {
					drive-strength = [02];
				};

				pins_dat {
					drive-strength = [02];
				};

				pins_clk {
					drive-strength = [03];
				};
			};

			mmc1@ddr50 {
				linux,phandle = <0xa>;
				phandle = <0xa>;

				pins_cmd {
					drive-strength = [02];
				};

				pins_dat {
					drive-strength = [02];
				};

				pins_clk {
					drive-strength = [03];
				};
			};

			mmc1@register_default {
				dat0rddly = [00];
				dat1rddly = [00];
				dat2rddly = [00];
				dat3rddly = [00];
				datwrddly = [00];
				cmdrrddly = [00];
				cmdrddly = [00];
				cmd_edge = [01];
				rdata_edge = [01];
				wdata_edge = [01];
				linux,phandle = <0xb>;
				phandle = <0xb>;
			};

			alspspincfg {
				linux,phandle = <0x62>;
				phandle = <0x62>;

				pins_cmd_dat {
					pins = <0x1206>;
					slew-rate = <0x0>;
					bias-pull-up = <0x0>;
				};
			};

			alspsdefaultcfg {
				linux,phandle = <0x61>;
				phandle = <0x61>;
			};

			gyropincfg {
				linux,phandle = <0x64>;
				phandle = <0x64>;

				pins_cmd_dat {
					pins = <0x2200>;
					slew-rate = <0x0>;
					bias-pull-down = <0x0>;
				};
			};

			gyrodefaultcfg {
				linux,phandle = <0x63>;
				phandle = <0x63>;
			};

			eint0default {
				linux,phandle = <0x15>;
				phandle = <0x15>;
			};

			eint@0 {
				linux,phandle = <0x16>;
				phandle = <0x16>;

				pins_cmd_dat {
					pins = <0xe06>;
					slew-rate = <0x0>;
					bias-disable;
				};
			};

			toucheint5default {
				linux,phandle = <0xf>;
				phandle = <0xf>;
			};

			toucheint@5 {
				linux,phandle = <0x10>;
				phandle = <0x10>;

				pins_cmd_dat {
					pins = <0x506>;
					slew-rate = <0x0>;
					bias-disable;
				};
			};

			eintoutput0 {
				linux,phandle = <0x11>;
				phandle = <0x11>;

				pins_cmd_dat {
					pins = <0x500>;
					slew-rate = <0x1>;
					output-low;
				};
			};

			eintoutput1 {
				linux,phandle = <0x12>;
				phandle = <0x12>;

				pins_cmd_dat {
					pins = <0x500>;
					slew-rate = <0x1>;
					output-high;
				};
			};

			rstoutput0 {
				linux,phandle = <0x13>;
				phandle = <0x13>;

				pins_cmd_dat {
					pins = <0x600>;
					slew-rate = <0x1>;
					output-low;
				};
			};

			rstoutput1 {
				linux,phandle = <0x14>;
				phandle = <0x14>;

				pins_cmd_dat {
					pins = <0x600>;
					slew-rate = <0x1>;
					output-high;
				};
			};

			audiodefault {
				linux,phandle = <0x3a>;
				phandle = <0x3a>;
			};

			pmicclkmode0 {
				linux,phandle = <0x3b>;
				phandle = <0x3b>;

				pins_cmd0_dat {
					pins = <0x1a00>;
				};

				pins_cmd1_dat {
					pins = <0x1c00>;
				};

				pins_cmd2_dat {
					pins = <0x1b00>;
				};
			};

			pmicclkmode1 {
				linux,phandle = <0x3c>;
				phandle = <0x3c>;

				pins_cmd0_dat {
					pins = <0x1a01>;
				};

				pins_cmd1_dat {
					pins = <0x1c01>;
				};

				pins_cmd2_dat {
					pins = <0x1b01>;
				};
			};

			audexamphigh {
				linux,phandle = <0x3d>;
				phandle = <0x3d>;

				pins_cmd_dat {
					pins = <0x1100>;
					slew-rate = <0x1>;
					output-high;
				};
			};

			audexamplow {
				linux,phandle = <0x3e>;
				phandle = <0x3e>;

				pins_cmd_dat {
					pins = <0x1100>;
					slew-rate = <0x1>;
					output-low;
				};
			};

			audheadsetswhigh {
				linux,phandle = <0x3f>;
				phandle = <0x3f>;

				pins_cmd_dat {
					pins = <0x1100>;
					slew-rate = <0x1>;
					output-high;
				};
			};

			audheadsetswlow {
				linux,phandle = <0x40>;
				phandle = <0x40>;

				pins_cmd_dat {
					pins = <0x1100>;
					slew-rate = <0x1>;
					output-low;
				};
			};

			cam0@0 {
				linux,phandle = <0x46>;
				phandle = <0x46>;

				pins_cmd_dat {
					pins = <0x4900>;
					slew-rate = <0x1>;
					output-low;
				};
			};

			cam0@1 {
				linux,phandle = <0x47>;
				phandle = <0x47>;

				pins_cmd_dat {
					pins = <0x4900>;
					slew-rate = <0x1>;
					output-high;
				};
			};

			cam0@2 {
				linux,phandle = <0x48>;
				phandle = <0x48>;

				pins_cmd_dat {
					pins = <0x4700>;
					slew-rate = <0x1>;
					output-low;
				};
			};

			cam0@3 {
				linux,phandle = <0x49>;
				phandle = <0x49>;

				pins_cmd_dat {
					pins = <0x4700>;
					slew-rate = <0x1>;
					output-high;
				};
			};

			cam1@0 {
				linux,phandle = <0x4a>;
				phandle = <0x4a>;

				pins_cmd_dat {
					pins = <0x4c00>;
					slew-rate = <0x1>;
					output-low;
				};
			};

			cam1@1 {
				linux,phandle = <0x4b>;
				phandle = <0x4b>;

				pins_cmd_dat {
					pins = <0x4c00>;
					slew-rate = <0x1>;
					output-high;
				};
			};

			cam1@2 {
				linux,phandle = <0x4c>;
				phandle = <0x4c>;

				pins_cmd_dat {
					pins = <0x4a00>;
					slew-rate = <0x1>;
					output-low;
				};
			};

			cam1@3 {
				linux,phandle = <0x4d>;
				phandle = <0x4d>;

				pins_cmd_dat {
					pins = <0x4a00>;
					slew-rate = <0x1>;
					output-high;
				};
			};

			cam@0 {
				linux,phandle = <0x4e>;
				phandle = <0x4e>;
			};

			cam@1 {
				linux,phandle = <0x4f>;
				phandle = <0x4f>;
			};

			camdefault {
				linux,phandle = <0x45>;
				phandle = <0x45>;
			};

			cam1serial@0 {
				linux,phandle = <0x50>;
				phandle = <0x50>;

				pins_cmd_dat {
					pins = <0x2302>;
				};

				pins_cmd_dat1 {
					pins = <0x2402>;
				};

				pins_cmd_dat2 {
					pins = <0x2502>;
				};

				pins_cmd_dat3 {
					pins = <0x2602>;
				};

				pins_cmd_dat4 {
					pins = <0x2702>;
				};
			};

			cam1mipi@0 {
				linux,phandle = <0x51>;
				phandle = <0x51>;

				pins_cmd_dat {
					pins = <0x2301>;
				};

				pins_cmd_dat1 {
					pins = <0x2401>;
				};

				pins_cmd_dat2 {
					pins = <0x2501>;
				};

				pins_cmd_dat3 {
					pins = <0x2601>;
				};

				pins_cmd_dat4 {
					pins = <0x2701>;
				};

				pins_cmd_dat5 {
					pins = <0x2801>;
				};
			};

			mclk1enable@0 {
				linux,phandle = <0x52>;
				phandle = <0x52>;

				pins_cmd_dat {
					pins = <0x4801>;
				};
			};

			mclk1disable@0 {
				linux,phandle = <0x53>;
				phandle = <0x53>;

				pins_cmd_dat {
					pins = <0x4800>;
				};
			};

			mclk2enable@0 {
				linux,phandle = <0x54>;
				phandle = <0x54>;

				pins_cmd_dat {
					pins = <0x4b01>;
				};
			};

			mclk2disable@0 {
				linux,phandle = <0x55>;
				phandle = <0x55>;

				pins_cmd_dat {
					pins = <0x4b00>;
				};
			};

			cam_sub_id {
				linux,phandle = <0x56>;
				phandle = <0x56>;

				pins_cmd_dat {
					pins = <0x1500>;
					slew-rate = <0x0>;
					bias-disable;
				};
			};

			cam_main_id {
				linux,phandle = <0x57>;
				phandle = <0x57>;

				pins_cmd_dat {
					pins = <0x1000>;
					slew-rate = <0x0>;
					bias-disable;
				};
			};

			cam_main2_id {
				linux,phandle = <0x58>;
				phandle = <0x58>;

				pins_cmd_dat {
					pins = <0x1400>;
					slew-rate = <0x0>;
					bias-disable;
				};
			};

			cam2@0 {
				linux,phandle = <0x59>;
				phandle = <0x59>;

				pins_cmd_dat {
					pins = <0x700>;
					slew-rate = <0x1>;
					output-low;
				};
			};

			cam2@1 {
				linux,phandle = <0x5a>;
				phandle = <0x5a>;

				pins_cmd_dat {
					pins = <0x700>;
					slew-rate = <0x1>;
					output-high;
				};
			};

			cam2@2 {
				linux,phandle = <0x5b>;
				phandle = <0x5b>;

				pins_cmd_dat {
					pins = <0x800>;
					slew-rate = <0x1>;
					output-low;
				};
			};

			cam2@3 {
				linux,phandle = <0x5c>;
				phandle = <0x5c>;

				pins_cmd_dat {
					pins = <0x800>;
					slew-rate = <0x1>;
					output-high;
				};
			};

			mipi_to_cam2_oe {
				linux,phandle = <0x5d>;
				phandle = <0x5d>;

				pins_cmd_dat {
					pins = <0x5300>;
					slew-rate = <0x1>;
					output-low;
				};
			};

			mipi_to_cam2_sel {
				linux,phandle = <0x5e>;
				phandle = <0x5e>;

				pins_cmd_dat {
					pins = <0x5100>;
					slew-rate = <0x1>;
					output-low;
				};
			};

			mipi_to_cam1_oe {
				linux,phandle = <0x5f>;
				phandle = <0x5f>;

				pins_cmd_dat {
					pins = <0x5300>;
					slew-rate = <0x1>;
					output-low;
				};
			};

			mipi_to_cam1_sel {
				linux,phandle = <0x60>;
				phandle = <0x60>;

				pins_cmd_dat {
					pins = <0x5100>;
					slew-rate = <0x1>;
					output-high;
				};
			};

			default {
				linux,phandle = <0x31>;
				phandle = <0x31>;
			};

			gpslna@0 {
				linux,phandle = <0x32>;
				phandle = <0x32>;

				pins_cmd_dat {
					pins = <0x5400>;
					slew-rate = <0x0>;
					bias-disable;
					output-low;
				};
			};

			gpslna@1 {
				linux,phandle = <0x33>;
				phandle = <0x33>;

				pins_cmd_dat {
					pins = <0x5400>;
					slew-rate = <0x1>;
					output-high;
				};
			};

			gpslna@2 {
				linux,phandle = <0x34>;
				phandle = <0x34>;

				pins_cmd_dat {
					pins = <0x5400>;
					slew-rate = <0x1>;
					output-low;
				};
			};

			usb_default {
				linux,phandle = <0x35>;
				phandle = <0x35>;
			};

			iddig_irq_init {
				linux,phandle = <0x36>;
				phandle = <0x36>;

				pins_cmd_dat {
					pins = <0x906>;
					slew-rate = <0x0>;
					bias-pull-up = <0x0>;
				};
			};

			drvvbus_init {
				linux,phandle = <0x37>;
				phandle = <0x37>;

				pins_cmd_dat {
					pins = <0xc00>;
					slew-rate = <0x1>;
					bias-pull-down = <0x0>;
				};
			};

			drvvbus_low {
				linux,phandle = <0x38>;
				phandle = <0x38>;

				pins_cmd_dat {
					pins = <0xc00>;
					slew-rate = <0x1>;
					output-low;
					bias-pull-down = <0x0>;
				};
			};

			drvvbus_high {
				linux,phandle = <0x39>;
				phandle = <0x39>;

				pins_cmd_dat {
					pins = <0xc00>;
					slew-rate = <0x1>;
					output-high;
					bias-pull-down = <0x0>;
				};
			};

			pins_cfg {
				linux,phandle = <0x66>;
				phandle = <0x66>;

				pins_cmd_dat {
					pins = <0x5206>;
					slew-rate = <0x0>;
					bias-disable;
				};
			};

			pins_default {
				linux,phandle = <0x65>;
				phandle = <0x65>;
			};

			main_ktd265_en@0 {
				linux,phandle = <0x21>;
				phandle = <0x21>;

				pins_cmd_dat {
					pins = <0xa00>;
					slew-rate = <0x1>;
					output-low;
				};
			};

			main_ktd265_en@1 {
				linux,phandle = <0x22>;
				phandle = <0x22>;

				pins_cmd_dat {
					pins = <0xa00>;
					slew-rate = <0x1>;
					output-high;
				};
			};

			main_ktd265_mode@0 {
				linux,phandle = <0x23>;
				phandle = <0x23>;

				pins_cmd_dat {
					pins = <0xb00>;
					slew-rate = <0x1>;
					output-low;
				};
			};

			main_ktd265_mode@1 {
				linux,phandle = <0x24>;
				phandle = <0x24>;

				pins_cmd_dat {
					pins = <0xb00>;
					slew-rate = <0x1>;
					output-high;
				};
			};

			main_wd3124db_en@0 {
				linux,phandle = <0x25>;
				phandle = <0x25>;

				pins_cmd_dat {
					pins = <0xa00>;
					slew-rate = <0x1>;
					output-low;
				};
			};

			main_wd3124db_en@1 {
				linux,phandle = <0x26>;
				phandle = <0x26>;

				pins_cmd_dat {
					pins = <0xa00>;
					slew-rate = <0x1>;
					output-high;
				};
			};

			main_wd3124db_flash@0 {
				linux,phandle = <0x27>;
				phandle = <0x27>;

				pins_cmd_dat {
					pins = <0xb00>;
					slew-rate = <0x1>;
					output-low;
				};
			};

			main_wd3124db_flash@1 {
				linux,phandle = <0x28>;
				phandle = <0x28>;

				pins_cmd_dat {
					pins = <0xb00>;
					slew-rate = <0x1>;
					output-high;
				};
			};

			main_fake_en@0 {
				linux,phandle = <0x29>;
				phandle = <0x29>;

				pins_cmd_dat {
					pins = <0x400>;
					slew-rate = <0x1>;
					output-low;
				};
			};

			main_fake_en@1 {
				linux,phandle = <0x2a>;
				phandle = <0x2a>;

				pins_cmd_dat {
					pins = <0x400>;
					slew-rate = <0x1>;
					output-high;
				};
			};

			sub_fake_en@0 {
				linux,phandle = <0x2b>;
				phandle = <0x2b>;

				pins_cmd_dat {
					pins = <0x900>;
					slew-rate = <0x1>;
					output-low;
				};
			};

			sub_fake_en@1 {
				linux,phandle = <0x2c>;
				phandle = <0x2c>;

				pins_cmd_dat {
					pins = <0x900>;
					slew-rate = <0x1>;
					output-high;
				};
			};

			gpiodefault {
				linux,phandle = <0x17>;
				phandle = <0x17>;
			};

			spi_int_init {
				linux,phandle = <0x18>;
				phandle = <0x18>;

				pins_cmd_dat {
					pins = <0xf06>;
					slew-rate = <0x0>;
					bias-disable;
				};
			};

			spi_int_out0@0 {
				linux,phandle = <0x19>;
				phandle = <0x19>;

				pins_cmd_dat {
					pins = <0xf00>;
					slew-rate = <0x1>;
					output-low;
				};
			};

			spi_int_out1@1 {
				linux,phandle = <0x1a>;
				phandle = <0x1a>;

				pins_cmd_dat {
					pins = <0xf00>;
					slew-rate = <0x1>;
					output-high;
				};
			};

			spi_rst_out0@0 {
				linux,phandle = <0x1b>;
				phandle = <0x1b>;

				pins_cmd_dat {
					pins = <0x1300>;
					slew-rate = <0x1>;
					output-low;
				};
			};

			spi_rst_out1@1 {
				linux,phandle = <0x1c>;
				phandle = <0x1c>;

				pins_cmd_dat {
					pins = <0x1300>;
					slew-rate = <0x1>;
					output-high;
				};
			};

			spi_cs_init@0 {
				linux,phandle = <0x1d>;
				phandle = <0x1d>;

				pins_cmd_dat {
					pins = <0x1>;
					slew-rate = <0x1>;
					bias-pull-up = <0x0>;
				};
			};

			spi_ck_init@0 {
				linux,phandle = <0x1e>;
				phandle = <0x1e>;

				pins_cmd_dat {
					pins = <0x101>;
					slew-rate = <0x1>;
					bias-pull-up = <0x0>;
				};
			};

			spi_mosi_init@0 {
				linux,phandle = <0x1f>;
				phandle = <0x1f>;

				pins_cmd_dat {
					pins = <0x201>;
					slew-rate = <0x1>;
					bias-pull-up = <0x0>;
				};
			};

			spi_miso_init@0 {
				linux,phandle = <0x20>;
				phandle = <0x20>;

				pins_cmd_dat {
					pins = <0x301>;
					slew-rate = <0x0>;
					bias-pull-up = <0x0>;
				};
			};
		};

		i2c@11009000 {
			compatible = "mediatek,mt6580-i2c", "mediatek,i2c0";
			cell-index = <0x0>;
			reg = <0x11009000 0x1000>;
			interrupts = <0x0 0x28 0x8 0x0 0x32 0x8>;
			clock-div = <0xa>;
			#address-cells = <0x1>;
			#size-cells = <0x0>;

			camera_main@36 {
				compatible = "mediatek,camera_main";
				reg = <0x36>;
				status = "okay";
			};

			camera_main_af@0c {
				compatible = "mediatek,camera_main_af";
				reg = <0xc>;
				status = "okay";
			};

			camera_sub@21 {
				compatible = "mediatek,camera_sub";
				reg = <0x21>;
				status = "okay";
			};
		};

		i2c@1100a000 {
			compatible = "mediatek,mt6580-i2c", "mediatek,i2c1";
			cell-index = <0x1>;
			reg = <0x1100a000 0x1000>;
			interrupts = <0x0 0x29 0x8 0x0 0x33 0x8>;
			clock-div = <0xa>;
			#address-cells = <0x1>;
			#size-cells = <0x0>;

			cap_touch@5d {
				compatible = "mediatek,cap_touch";
				reg = <0x38>;
				status = "okay";
			};

			ext_buck@60 {
				compatible = "mediatek,ext_buck";
				reg = <0x60>;
				status = "okay";
			};
		};

		i2c@1100b000 {
			compatible = "mediatek,mt6580-i2c", "mediatek,i2c2";
			cell-index = <0x2>;
			reg = <0x1100b000 0x1000>;
			interrupts = <0x0 0x2a 0x8 0x0 0x34 0x8>;
			clock-div = <0xa>;
			#address-cells = <0x1>;
			#size-cells = <0x0>;

			strobe_main@63 {
				compatible = "mediatek,strobe_main";
				reg = <0x63>;
				status = "okay";
			};

			msensor@0d {
				compatible = "mediatek,msensor";
				reg = <0xd>;
				status = "okay";
			};

			gsensor@4c {
				compatible = "mediatek,gsensor";
				reg = <0x4c>;
				status = "okay";
			};

			gyro@68 {
				compatible = "mediatek,gyro";
				reg = <0x68>;
				status = "okay";
			};

			alsps@49 {
				compatible = "mediatek,alsps";
				reg = <0x49>;
				status = "okay";
			};
		};

		touch@0 {
			compatible = "mediatek,mt6580-touch";
			vtouch-supply = <0xe>;
			interrupt-parent = <0xc>;
			interrupts = <0x5 0x2>;
			debounce = <0x5 0x0>;
			status = "okay";
			tpd-resolution = <0x2d0 0x500>;
			use-tpd-button = <0x1>;
			tpd-key-num = <0x3>;
			tpd-key-local = <0x8b 0xac 0x9e 0x0>;
			tpd-key-dim-local = <0x5a 0x373 0x64 0x28 0xe6 0x373 0x64 0x28 0x172 0x373 0x64 0x28 0x0 0x0 0x0 0x0>;
			tpd-max-touch-num = <0x5>;
			tpd-filter-enable = <0x0>;
			tpd_eint_gpio = <5 6>;
			tpd-filter-pixel-density = <0x7c>;
			tpd-filter-custom-prameters = <0x0 0x0 0x0 0x0 0x0 0x0 0x0 0x0 0x0 0x0 0x0 0x0>;
			tpd-filter-custom-speed = <0x0 0x0 0x0>;
			pinctrl-names = "default", "state_eint_as_int", "state_eint_output0", "state_eint_output1", "state_rst_output0", "state_rst_output1";
			pinctrl-0 = <0xf>;
			pinctrl-1 = <0x10>;
			pinctrl-2 = <0x11>;
			pinctrl-3 = <0x12>;
			pinctrl-4 = <0x13>;
			pinctrl-5 = <0x14>;
		};

		accdet {
			compatible = "mediatek,mt6580-accdet";
			interrupt-parent = <0xc>;
			interrupts = <0xe 0x8>;
			debounce = <0xe 0x3e800>;
			status = "okay";
			accdet-mic-vol = <0x7>;
			headset-mode-setting = <0x500 0x600 0x1 0x1f0 0x800 0x800 0x20>;
			accdet-plugout-debounce = <0x14>;
			accdet-mic-mode = <0x1>;
			headset-three-key-threshold = <0x0 0x5a 0xf0 0x1f4>;
			headset-four-key-threshold = <0 59 123 195 450>;
			pinctrl-names = "default", "state_eint_as_int";
			pinctrl-0 = <0x15>;
			pinctrl-1 = <0x16>;
		};

		fingerprint@ {
			compatible = "mediatek,fingerprint";
			vfingerprint-supply = <0xe>;
			pinctrl-names = "default", "state_spi_eint_init", "state_eint_pull_down", "state_eint_pull_disable", "state_spi_rst_low", "state_spi_rst_high", "state_spi_cs_init", "state_spi_ck_init", "state_spi_mosi_init", "state_spi_miso_init";
			pinctrl-0 = <0x17>;
			pinctrl-1 = <0x18>;
			pinctrl-2 = <0x19>;
			pinctrl-3 = <0x1a>;
			pinctrl-4 = <0x1b>;
			pinctrl-5 = <0x1c>;
			pinctrl-6 = <0x1d>;
			pinctrl-7 = <0x1e>;
			pinctrl-8 = <0x1f>;
			pinctrl-9 = <0x20>;
			interrupt-parent = <0xc>;
			interrupts = <0xf 0x2>;
			debounce = <0xf 0x0>;
			status = "okay";
		};

		gse_1 {
			compatible = "mediatek, gse_1-eint";
			status = "disabled";
		};

		spi@1100c000 {
			compatible = "mediatek,mt6580-spi";
			cell-index = <0x0>;
			reg = <0x1100c000 0x1000>;
			interrupts = <0x0 0x40 0x8>;
			mediatek,spi-padmacro = <0x0>;
		};

		THERM_CTRL@0x1100D000 {
			compatible = "mediatek,THERM_CTRL";
			reg = <0x1100d000 0x1000>;
			interrupts = <0x0 0x25 0x8>;
		};

		btif_tx@11000380 {
			compatible = "mediatek,btif_tx";
			reg = <0x11000380 0x80>;
			interrupts = <0x0 0x36 0x8>;
		};

		btif_rx@11000400 {
			compatible = "mediatek,btif_rx";
			reg = <0x11000400 0x80>;
			interrupts = <0x0 0x37 0x8>;
		};

		btif@1100e000 {
			compatible = "mediatek,btif";
			reg = <0x1100e000 0x1000>;
			interrupts = <0x0 0x43 0x8>;
		};

		gps {
			compatible = "mediatek,gps";
		};

		flashlight@ {
			compatible = "mediatek,flashlight-custom";
			flashlight_main_support = <0x1 0x3>;
			flashlight_sub_support = <0x1 0x1>;
			flashlight_isnk_num = <0x0 0x0 0x1 0x1>;
			pinctrl-names = "default", "main_ktd265_en_pin_low", "main_ktd265_en_pin_high", "main_ktd265_mode_pin_low", "main_ktd265_mode_pin_high", "main_wd3124db_en_pin_low", "main_wd3124db_en_pin_high", "main_wd3124db_flash_pin_low", "main_wd3124db_flash_pin_high", "main_fake_en_pin_low", "main_fake_en_pin_high", "sub_fake_en_pin_low", "sub_fake_en_pin_high";
			pinctrl-0 = <0x17>;
			pinctrl-1 = <0x21>;
			pinctrl-2 = <0x22>;
			pinctrl-3 = <0x23>;
			pinctrl-4 = <0x24>;
			pinctrl-5 = <0x25>;
			pinctrl-6 = <0x26>;
			pinctrl-7 = <0x27>;
			pinctrl-8 = <0x28>;
			pinctrl-9 = <0x29>;
			pinctrl-10 = <0x2a>;
			pinctrl-11 = <0x2b>;
			pinctrl-12 = <0x2c>;
			status = "okay";
		};

		BTCVSD@0x18000000 {
			compatible = "mediatek,audio_bt_cvsd";
			offset = <0xc00 0x2 0xfd0 0xfd4 0xfd8>;
			reg = <0x10001000 0x1000 0x18000000 0x10000 0x18080000 0x8000>;
			interrupts = <0x0 0x99 0x8>;
		};

		consys@18070000 {
			compatible = "mediatek,mt6580-consys";
			reg = <0x18070000 0x200 0x10007000 0x100 0x10000000 0x2000 0x10006000 0x1000 0x10005000 0x1000>;
			interrupts = <0x0 0x9a 0x8 0x0 0x9c 0x8>;
			vcn18-supply = <0x2d>;
			vcn28-supply = <0x2e>;
			vcn33_bt-supply = <0x2f>;
			vcn33_wifi-supply = <0x30>;
			pinctrl-names = "default", "gps_lna_state_init", "gps_lna_state_oh", "gps_lna_state_ol";
			pinctrl-0 = <0x31>;
			pinctrl-1 = <0x32>;
			pinctrl-2 = <0x33>;
			pinctrl-3 = <0x34>;
			status = "okay";
		};

		WIFI@0x180F0000 {
			compatible = "mediatek,WIFI";
			reg = <0x180f0000 0x5c>;
			interrupts = <0x0 0x9b 0x8>;
		};

		DISP_PWM@0x1100F000 {
			compatible = "mediatek,DISP_PWM";
			reg = <0x1100f000 0x1000>;
			interrupts = <0x0 0x21 0x8>;
		};

		USB0@0x11100000 {
			compatible = "mediatek,USB0";
			cell-index = <0x0>;
			reg = <0x11100000 0x10000 0x11110000 0x10000>;
			interrupts = <0x0 0x20 0x8>;
			mode = <0x2>;
			multipoint = <0x1>;
			dyn_fifo = <0x1>;
			soft_con = <0x1>;
			dma = <0x1>;
			num_eps = <0x10>;
			dma_channels = <0x8>;
			iddig_gpio = <0x9 0x6>;
			drvvbus_gpio = <0xc 0x0>;
			pinctrl-names = "usb_default", "iddig_irq_init", "drvvbus_init", "drvvbus_low", "drvvbus_high";
			pinctrl-0 = <0x35>;
			pinctrl-1 = <0x36>;
			pinctrl-2 = <0x37>;
			pinctrl-3 = <0x38>;
			pinctrl-4 = <0x39>;
			status = "okay";

			usbiddig {
				compatible = "mediatek,usb_iddig_eint";
			};
		};

		otg_iddig {
			compatible = "mediatek,otg_iddig";
			interrupt-parent = <0xc>;
			interrupts = <0x9 0x8>;
			debounce = <0x9 0x3e800>;
			status = "okay";
		};

		usbphy@0 {
			compatible = "usb-nop-xceiv";
		};

		audio@11140000 {
			compatible = "mediatek,audio";
			reg = <0x11140000 0x10000>;
			interrupts = <0x0 0x50 0x8>;
		};

		mt_soc_dl1_pcm@11140000 {
			compatible = "mediatek,mt_soc_pcm_dl1";
			reg = <0x11140000 0x1000>;
			interrupts = <0x0 0x50 0x8>;
			audclk-gpio = <0x1a 0x0>;
			audmiso-gpio = <0x1c 0x0>;
			audmosi-gpio = <0x1b 0x0>;
			pinctrl-names = "default", "audpmicclk-mode0", "audpmicclk-mode1", "extamp-pullhigh", "extamp-pulllow", "headsetsw-pullhigh", "headsetsw-pulllow";
			pinctrl-0 = <0x3a>;
			pinctrl-1 = <0x3b>;
			pinctrl-2 = <0x3c>;
			pinctrl-3 = <0x3d>;
			pinctrl-4 = <0x3e>;
			pinctrl-5 = <0x3f>;
			pinctrl-6 = <0x40>;
			status = "okay";
		};

		mt_soc_ul1_PCM@11140000 {
			compatible = "mediatek,mt_soc_pcm_capture";
		};

		mt_soc_voice_md1@11140000 {
			compatible = "mediatek,mt_soc_pcm_voice_md1";
		};

		mt_soc_hdmi_pcm@11140000 {
			compatible = "mediatek,mt_soc_pcm_hdmi";
		};

		mt_soc_uldlloopback_pcm@11140000 {
			compatible = "mediatek,mt_soc_pcm_uldlloopback";
		};

		mt_soc_i2s0_pcm@11140000 {
			compatible = "mediatek,mt_soc_pcm_dl1_i2s0";
		};

		mt_soc_mrgrx_pcm@11140000 {
			compatible = "mediatek,mt_soc_pcm_mrgrx";
		};

		mt_soc_mrgrx_awb_pcm@11140000 {
			compatible = "mediatek,mt_soc_pcm_mrgrx_awb";
		};

		mt_soc_fm_i2s_pcm@0x11140000 {
			compatible = "mediatek,mt_soc_pcm_fm_i2s";
		};

		mt_soc_fm_i2s_awb_pcm@11140000 {
			compatible = "mediatek,mt_soc_pcm_fm_i2s_awb";
		};

		mt_soc_i2s0dl1_pcm@11140000 {
			compatible = "mediatek,mt_soc_pcm_dl1_i2s0Dl1";
		};

		mt_soc_dl1_awb_pcm@11140000 {
			compatible = "mediatek,mt_soc_pcm_dl1_awb";
		};

		mt_soc_voice_md1_bt@11140000 {
			compatible = "mediatek,mt_soc_pcm_voice_md1_bt";
		};

		mt_soc_voip_bt_out@11140000 {
			compatible = "mediatek,mt_soc_pcm_dl1_bt";
		};

		mt_soc_voip_bt_in@11140000 {
			compatible = "mediatek,mt_soc_pcm_bt_dai";
		};

		mt_soc_tdmrx_pcm@11140000 {
			compatible = "mediatek,mt_soc_tdm_capture";
		};

		mt_soc_fm_mrgtx_pcm@11140000 {
			compatible = "mediatek,mt_soc_pcm_fmtx";
		};

		mt_soc_ul2_pcm@11140000 {
			compatible = "mediatek,mt_soc_pcm_capture2";
		};

		mt_soc_i2s0_awb_pcm@11140000 {
			compatible = "mediatek,mt_soc_pcm_i2s0_awb";
		};

		mt_soc_voice_md2@11140000 {
			compatible = "mediatek,mt_soc_pcm_voice_md2";
		};

		mt_soc_routing_pcm@11140000 {
			compatible = "mediatek,mt_soc_pcm_routing";
		};

		mt_soc_voice_md2_bt@11140000 {
			compatible = "mediatek,mt_soc_pcm_voice_md2_bt";
		};

		mt_soc_hp_impedance_pcm@11140000 {
			compatible = "mediatek,Mt_soc_pcm_hp_impedance";
		};

		mt_soc_codec_name@11140000 {
			compatible = "mediatek,mt_soc_codec_63xx";
		};

		mt_soc_dummy_pcm@11140000 {
			compatible = "mediatek,mt_soc_pcm_dummy";
		};

		mt_soc_codec_dummy_name@11140000 {
			compatible = "mediatek,mt_soc_codec_dummy";
		};

		mt_soc_routing_dai_name@11140000 {
			compatible = "mediatek,mt_soc_dai_routing";
		};

		mt_soc_dai_name@11140000 {
			compatible = "mediatek,mt_soc_dai_stub";
		};

		mt_soc_dl2_pcm@11140000 {
			compatible = "mediatek,mt_soc_pcm_dl2";
		};

		AHB_MOM@0x11150000 {
			compatible = "mediatek,AHB_MOM";
			reg = <0x11150000 0x10000>;
		};

		MDI@0x11160000 {
			compatible = "mediatek,MDI";
			reg = <0x11160000 0x10000>;
		};

		G3D_CONFIG@0x13000000 {
			compatible = "mediatek,G3D_CONFIG";
			reg = <0x13000000 0x1000>;
		};

		MALI@0x13010000 {
			compatible = "mediatek,MALI";
			reg = <0x13010000 0x10000>;
		};

		mmsys_config@14000000 {
			compatible = "mediatek,mmsys_config";
			reg = <0x14000000 0x1000>;
			interrupts = <0x0 0x84 0x8>;
		};

		mdp_rdma@14001000 {
			compatible = "mediatek,mdp_rdma";
			reg = <0x14001000 0x1000>;
			interrupts = <0x0 0x71 0x8>;
		};

		mdp_rsz0@14002000 {
			compatible = "mediatek,mdp_rsz0";
			reg = <0x14002000 0x1000>;
			interrupts = <0x0 0x72 0x8>;
		};

		mdp_rsz1@14003000 {
			compatible = "mediatek,mdp_rsz1";
			reg = <0x14003000 0x1000>;
			interrupts = <0x0 0x73 0x8>;
		};

		mdp_wdma@14004000 {
			compatible = "mediatek,mdp_wdma";
			reg = <0x14004000 0x1000>;
			interrupts = <0x0 0x75 0x8>;
		};

		mdp_wrot@14005000 {
			compatible = "mediatek,mdp_wrot";
			reg = <0x14005000 0x1000>;
			interrupts = <0x0 0x76 0x8>;
		};

		mdp_tdshp@14006000 {
			compatible = "mediatek,mdp_tdshp";
			reg = <0x14006000 0x1000>;
			interrupts = <0x0 0x74 0x8>;
		};

		lcm {
			compatible = "mediatek,mt6580-lcm";
		};

		nfc {
			compatible = "mediatek,nfc-gpio-v2";
			gpio-ven = <0xb>;
			gpio-rst = <0xa>;
			gpio-eint = <0xc>;
			gpio-irq = <0x9>;
		};

		DISPSYS@0x14007000 {
			compatible = "mediatek,DISPSYS";
			reg = <0x14000000 0x1000 0x14007000 0x1000 0x14008000 0x1000 0x14009000 0x1000 0x1400a000 0x1000 0x1400b000 0x1000 0x1400c000 0x1000 0x1400d000 0x1000 0x1400e000 0x1000 0x1400f000 0x1000 0x14010000 0x1000 0x14011000 0x1000 0x14012000 0x1000 0x14013000 0x1000 0x1100f000 0x1000 0x14015000 0x1000 0x14016000 0x1000 0x14017000 0x1000 0x14018000 0x1000>;
			interrupts = <0x0 0x0 0x8 0x0 0x77 0x8 0x0 0x0 0x8 0x0 0x79 0x8 0x0 0x0 0x8 0x0 0x7b 0x8 0x0 0x7c 0x8 0x0 0x0 0x8 0x0 0x7e 0x8 0x0 0x7f 0x8 0x0 0x80 0x8 0x0 0x0 0x8 0x0 0x82 0x8 0x0 0x0 0x8 0x0 0x0 0x8 0x0 0x70 0x8 0x0 0x0 0x8 0x0 0x0 0x8 0x0 0x0 0x8>;
		};

		DISP_OVL0@0x14007000 {
			compatible = "mediatek,DISP_OVL0";
			reg = <0x14007000 0x1000>;
			interrupts = <0x0 0x77 0x8>;
		};

		DISP_OVL1@0x14008000 {
			compatible = "mediatek,DISP_OVL1";
			reg = <0x14008000 0x1000>;
		};

		DISP_RDMA0@0x14009000 {
			compatible = "mediatek,DISP_RDMA0";
			reg = <0x14009000 0x1000>;
			interrupts = <0x0 0x79 0x8>;
		};

		DISP_RDMA1@0x1400A000 {
			compatible = "mediatek,DISP_RDMA1";
			reg = <0x1400a000 0x1000>;
		};

		DISP_WDMA@0x1400B000 {
			compatible = "mediatek,DISP_WDMA";
			reg = <0x1400b000 0x1000>;
			interrupts = <0x0 0x7b 0x8>;
		};

		DISP_COLOR@0x1400C000 {
			compatible = "mediatek,DISP_COLOR";
			reg = <0x1400c000 0x1000>;
			interrupts = <0x0 0x7c 0x8>;
		};

		DISP_CCORR@0x1400D000 {
			compatible = "mediatek,DISP_CCORR";
			reg = <0x1400d000 0x1000>;
		};

		DISP_AAL@0x1400E000 {
			compatible = "mediatek,DISP_AAL";
			reg = <0x1400e000 0x1000>;
			interrupts = <0x0 0x7e 0x8>;
		};

		DISP_GAMMA@0x1400F000 {
			compatible = "mediatek,DISP_GAMMA";
			reg = <0x1400f000 0x1000>;
			interrupts = <0x0 0x7f 0x8>;
		};

		DISP_DITHER@0x14010000 {
			compatible = "mediatek,DISP_DITHER";
			reg = <0x14010000 0x1000>;
			interrupts = <0x0 0x80 0x8>;
		};

		DISP_UFOE@0x14011000 {
			compatible = "mediatek,DISP_UFOE";
			reg = <0x14011000 0x1000>;
		};

		DSI@0x14012000 {
			compatible = "mediatek,DSI";
			reg = <0x14012000 0x1000>;
		};

		DPI@0x14013000 {
			compatible = "mediatek,DPI";
			reg = <0x14013000 0x1000>;
		};

		PTP_FSM@0x1100D000 {
			compatible = "mediatek,PTP_FSM";
			reg = <0x1100d000 0x1000>;
			interrupts = <0x0 0x2b 0x8>;
		};

		MM_MUTEX@0x14015000 {
			compatible = "mediatek,MM_MUTEX";
			reg = <0x14015000 0x1000>;
			interrupts = <0x0 0x70 0x8>;
		};

		SMI_LARB0@0x14016000 {
			compatible = "mediatek,SMI_LARB0";
			reg = <0x14016000 0x1000>;
			interrupts = <0x0 0x85 0x8>;
		};

		SMI_COMMON@0x14017000 {
			compatible = "mediatek,SMI_COMMON";
			reg = <0x14017000 0x1000 0x14016000 0x1000 0x15001000 0x1000>;
		};

		MIPI_TX_CONFIG@0x14018000 {
			compatible = "mediatek,MIPI_TX_CONFIG";
			reg = <0x14018000 0x1000>;
		};

		ISPSYS@0x15000000 {
			compatible = "mediatek,ISPSYS";
			reg = <0x15004000 0x9000 0x15000000 0x10000 0x10011000 0x4000 0x10017000 0x1000>;
			interrupts = <0x0 0x8e 0x8 0x0 0x8b 0x8>;
		};

		ISP_SYSR@0x15000000 {
			compatible = "mediatek,ISP_SYSR";
		};

		ISP_PIPEM@0x15000000 {
			compatible = "mediatek,ISP_PIPEM";
		};

		kd_camera_hw1@15008000 {
			compatible = "mediatek,camera_hw";
			reg = <0x15008000 0x1000>;
			vcama-supply = <0x41>;
			vcamd-supply = <0x42>;
			vcamaf-supply = <0x43>;
			vcamio-supply = <0x44>;
			vcamd_main2-supply = <0x42>;
			vcamd_sub-supply = <0x42>;
			vcamio_main2-supply = <0x44>;
			vcamio_sub-supply = <0x44>;
			vcama_main2-supply = <0x41>;
			vcama_sub-supply = <0x41>;
			status = "okay";
			pinctrl-names = "default", "cam0_rst0", "cam0_rst1", "cam0_pnd0", "cam0_pnd1", "cam1_rst0", "cam1_rst1", "cam1_pnd0", "cam1_pnd1", "cam_ldo0_0", "cam_ldo0_1", "cam1_gpio_serial", "cam1_gpio_mipi", "cam_mclk1_enable", "cam_mclk1_disable", "cam_mclk2_enable", "cam_mclk2_disable", "sub_cam_id", "main_cam_id", "main2_cam_id", "cam2_rst0", "cam2_rst1", "cam2_pnd0", "cam2_pnd1", "mipi_to_cam2_oe", "mipi_to_cam2_sel", "mipi_to_cam0_oe", "mipi_to_cam0_sel";
			pinctrl-0 = <0x45>;
			pinctrl-1 = <0x46>;
			pinctrl-2 = <0x47>;
			pinctrl-3 = <0x48>;
			pinctrl-4 = <0x49>;
			pinctrl-5 = <0x4a>;
			pinctrl-6 = <0x4b>;
			pinctrl-7 = <0x4c>;
			pinctrl-8 = <0x4d>;
			pinctrl-9 = <0x4e>;
			pinctrl-10 = <0x4f>;
			pinctrl-11 = <0x50>;
			pinctrl-12 = <0x51>;
			pinctrl-13 = <0x52>;
			pinctrl-14 = <0x53>;
			pinctrl-15 = <0x54>;
			pinctrl-16 = <0x55>;
			pinctrl-17 = <0x56>;
			pinctrl-18 = <0x57>;
			pinctrl-19 = <0x58>;
			pinctrl-20 = <0x59>;
			pinctrl-21 = <0x5a>;
			pinctrl-22 = <0x5b>;
			pinctrl-23 = <0x5c>;
			pinctrl-24 = <0x5d>;
			pinctrl-25 = <0x5e>;
			pinctrl-26 = <0x5f>;
			pinctrl-27 = <0x60>;
			sub_cam_id_gpio = <0x15>;
			main_cam_id_gpio = <0x10>;
			main2_cam_id_gpio = <0x14>;
		};

		kd_camera_hw2@15008000 {
			compatible = "mediatek,camera_hw2";
			reg = <0x15008000 0x1000>;
		};

		seninf_top@15008000 {
			compatible = "mediatek,SENINF_TOP";
			reg = <0x15008000 0x1000>;
			interrupts = <0x0 0x8e 0x8>;
		};

		CAM_0@0x15004000 {
			compatible = "mediatek,CAM_0";
			reg = <0x15004000 0x1000>;
			interrupts = <0x0 0x8b 0x8>;
		};

		CAM_1@0x15005000 {
			compatible = "mediatek,CAM_1";
			reg = <0x15005000 0x1000>;
		};

		VENC@0x15009000 {
			compatible = "mediatek,VENC";
			reg = <0x15009000 0x1000>;
			interrupts = <0x0 0x8a 0x8>;
		};

		VDEC@0x1500B000 {
			compatible = "mediatek,VDEC";
			reg = <0x1500b000 0x1000>;
			interrupts = <0x0 0x89 0x8>;
		};

		SMI_LARB1@0x15001000 {
			compatible = "mediatek,SMI_LARB1";
			reg = <0x15001000 0x1000>;
			interrupts = <0x0 0x88 0x8>;
		};

		IMGSYS_CONFIG@0x15000000 {
			compatible = "mediatek,IMGSYS_CONFIG";
			reg = <0x15000000 0x1000>;
		};

		hwmsensor@0 {
			compatible = "mediatek,hwmsensor";
		};

		gsensor@0 {
			compatible = "mediatek,gsensor";
		};

		als_ps@0 {
			compatible = "mediatek,als_ps";
			pinctrl-names = "pin_default", "pin_cfg";
			pinctrl-0 = <0x61>;
			pinctrl-1 = <0x62>;
			status = "okay";
		};

		m_acc_pl@0 {
			compatible = "mediatek,m_acc_pl";
		};

		m_alsps_pl@0 {
			compatible = "mediatek,m_alsps_pl";
		};

		sensorHub@0 {
			compatible = "mediatek,sensorHub";
		};

		shf@0 {
			compatible = "mediatek,shf";
		};

		m_batch_pl@0 {
			compatible = "mediatek,m_batch_pl";
		};

		gyroscope@0 {
			compatible = "mediatek,gyroscope";
			pinctrl-names = "pin_default", "pin_cfg";
			pinctrl-0 = <0x63>;
			pinctrl-1 = <0x64>;
			status = "okay";
		};

		m_gyro_pl@0 {
			compatible = "mediatek,m_gyro_pl";
		};

		barometer@0 {
			compatible = "mediatek,barometer";
		};

		m_baro_pl@0 {
			compatible = "mediatek,m_baro_pl";
		};

		msensor@0 {
			compatible = "mediatek,msensor";
		};

		m_mag_pl@0 {
			compatible = "mediatek,m_mag_pl";
		};

		orientation@0 {
			compatible = "mediatek,orientation";
		};

		pedometer@0 {
			compatible = "mediatek,pedometer";
		};

		m_pdr_pl@0 {
			compatible = "mediatek,m_pdr_pl";
		};

		step_counter@0 {
			compatible = "mediatek,step_counter";
		};

		m_step_c_pl@0 {
			compatible = "mediatek,m_step_c_pl";
		};

		in_pocket@0 {
			compatible = "mediatek,in_pocket";
		};

		m_inpk_pl@0 {
			compatible = "mediatek,m_inpk_pl";
		};

		shake@0 {
			compatible = "mediatek,shake";
		};

		m_shk_pl@0 {
			compatible = "mediatek,m_shk_pl";
		};

		face_down@0 {
			compatible = "mediatek,face_down";
		};

		m_fdn_pl@0 {
			compatible = "mediatek,m_fdn_pl";
		};

		activity@0 {
			compatible = "mediatek,activity";
		};

		m_act_pl@0 {
			compatible = "mediatek,m_act_pl";
		};

		heart_rate@0 {
			compatible = "mediatek,heart_rate";
		};

		m_hrm_pl@0 {
			compatible = "mediatek,m_hrm_pl";
		};

		tilt_detector@0 {
			compatible = "mediatek,tilt_detector";
		};

		m_tilt_pl@0 {
			compatible = "mediatek,m_tilt_pl";
		};

		wake_gesture@0 {
			compatible = "mediatek,wake_gesture";
		};

		m_wag_pl@0 {
			compatible = "mediatek,m_wag_pl";
		};

		glance_gesture@0 {
			compatible = "mediatek,glance_gesture";
		};

		m_glg_pl@0 {
			compatible = "mediatek,m_glg_pl";
		};

		pick_up@0 {
			compatible = "mediatek,pick_up";
		};

		m_pkup_pl@0 {
			compatible = "mediatek,m_pkup_pl";
		};

		alsps {
			compatible = "mediatek, als-eint";
			interrupt-parent = <0xc>;
			interrupts = <0x12 0x8>;
			debounce = <0x12 0x0>;
			status = "okay";
		};

		mtkfb@0 {
			compatible = "mediatek,mtkfb";
		};

		dsi_te {
			compatible = "mediatek, dsi_te-eint";
			interrupt-parent = <0xc>;
			interrupts = <0x44 0x1>;
			debounce = <0x44 0x0>;
			status = "okay";
		};

		mhall {
			compatible = "mediatek,mhall";
			interrupt-parent = <0xc>;
			interrupts = <0x52 0x8>;
			debounce = <0x52 0x0>;
			status = "okay";
			pinctrl-names = "default", "state_eint_as_int";
			pinctrl-0 = <0x65>;
			pinctrl-1 = <0x66>;
		};

		aw87319_pa {
			compatible = "mediatek,aw87319_pa";
		};
	};

	MOBICORE {
		compatible = "trustonic,mobicore";
		interrupts = <0x0 0x97 0x1>;
	};

	mt_pmic_regulator {
		compatible = "mediatek,mt_pmic";

		buck_regulators {
			compatible = "mediatek,mt_pmic_buck_regulators";

			buck_vpa {
				regulator-name = "vpa";
				regulator-min-microvolt = <0x7a120>;
				regulator-max-microvolt = <0x37b1d0>;
				regulator-ramp-delay = <0xc350>;
				regulator-enable-ramp-delay = <0xb4>;
			};

			buck_vproc {
				regulator-name = "vproc";
				regulator-min-microvolt = <0xaae60>;
				regulator-max-microvolt = <0x16caf6>;
				regulator-ramp-delay = <0x186a>;
				regulator-enable-ramp-delay = <0xb4>;
				regulator-always-on;
				regulator-boot-on;
			};
		};

		ldo_regulators {
			compatible = "mediatek,mt_pmic_ldo_regulators";

			ldo_vcn28 {
				regulator-name = "vcn28";
				regulator-min-microvolt = <0x1b7740>;
				regulator-max-microvolt = <0x2ab980>;
				regulator-enable-ramp-delay = <0x108>;
				regulator-default-on = <0x0>;
				status = "okay";
				linux,phandle = <0x2e>;
				phandle = <0x2e>;
			};

			ldo_vtcxo {
				regulator-name = "vtcxo";
				regulator-min-microvolt = <0x2191c0>;
				regulator-max-microvolt = <0x2191c0>;
				regulator-enable-ramp-delay = <0x6e>;
				linux,phandle = <0x67>;
				phandle = <0x67>;
			};

			ldo_va {
				regulator-name = "va";
				regulator-min-microvolt = <0x1b7740>;
				regulator-max-microvolt = <0x2625a0>;
				regulator-enable-ramp-delay = <0x6e>;
				linux,phandle = <0x68>;
				phandle = <0x68>;
			};

			ldo_vcama {
				regulator-name = "vcama";
				regulator-min-microvolt = <0x16e360>;
				regulator-max-microvolt = <0x2ab980>;
				regulator-enable-ramp-delay = <0x108>;
				regulator-default-on = <0x0>;
				status = "okay";
				linux,phandle = <0x41>;
				phandle = <0x41>;
			};

			ldo_vcn33_bt {
				regulator-name = "vcn33_bt";
				regulator-min-microvolt = <0x325aa0>;
				regulator-max-microvolt = <0x36ee80>;
				regulator-enable-ramp-delay = <0x108>;
				linux,phandle = <0x2f>;
				phandle = <0x2f>;
			};

			ldo_vcn33_wifi {
				regulator-name = "vcn33_wifi";
				regulator-min-microvolt = <0x325aa0>;
				regulator-max-microvolt = <0x36ee80>;
				regulator-enable-ramp-delay = <0x108>;
				linux,phandle = <0x30>;
				phandle = <0x30>;
			};

			ldo_vio28 {
				regulator-name = "vio28";
				regulator-min-microvolt = <0x2ab980>;
				regulator-max-microvolt = <0x2ab980>;
				regulator-enable-ramp-delay = <0x108>;
				regulator-boot-on;
				linux,phandle = <0x69>;
				phandle = <0x69>;
			};

			ldo_vsim1 {
				regulator-name = "vsim1";
				regulator-min-microvolt = <0x1b7740>;
				regulator-max-microvolt = <0x2dc6c0>;
				regulator-enable-ramp-delay = <0x108>;
				regulator-default-on = <0x0>;
				status = "okay";
				linux,phandle = <0x6a>;
				phandle = <0x6a>;
			};

			ldo_vsim2 {
				regulator-name = "vsim2";
				regulator-min-microvolt = <0x1b7740>;
				regulator-max-microvolt = <0x2dc6c0>;
				regulator-enable-ramp-delay = <0x108>;
				regulator-default-on = <0x0>;
				status = "okay";
				linux,phandle = <0x6b>;
				phandle = <0x6b>;
			};

			ldo_vusb {
				regulator-name = "vusb";
				regulator-min-microvolt = <0x325aa0>;
				regulator-max-microvolt = <0x325aa0>;
				regulator-enable-ramp-delay = <0x108>;
				regulator-boot-on;
				linux,phandle = <0x6c>;
				phandle = <0x6c>;
			};

			ldo_vgp1 {
				regulator-name = "vgp1";
				regulator-min-microvolt = <0x124f80>;
				regulator-max-microvolt = <0x325aa0>;
				regulator-enable-ramp-delay = <0x108>;
				regulator-default-on = <0x0>;
				status = "okay";
				linux,phandle = <0xe>;
				phandle = <0xe>;
			};

			ldo_vgp2 {
				regulator-name = "vgp2";
				regulator-min-microvolt = <0x124f80>;
				regulator-max-microvolt = <0x2dc6c0>;
				regulator-enable-ramp-delay = <0x108>;
				regulator-default-on = <0x0>;
				status = "okay";
				linux,phandle = <0x6d>;
				phandle = <0x6d>;
			};

			ldo_vemc_3v3 {
				regulator-name = "vemc_3v3";
				regulator-min-microvolt = <0x2dc6c0>;
				regulator-max-microvolt = <0x325aa0>;
				regulator-enable-ramp-delay = <0x108>;
				regulator-boot-on;
				regulator-default-on = <0x0>;
				status = "okay";
				linux,phandle = <0x6e>;
				phandle = <0x6e>;
			};

			ldo_vcamaf {
				regulator-name = "vcamaf";
				regulator-min-microvolt = <0x124f80>;
				regulator-max-microvolt = <0x325aa0>;
				regulator-enable-ramp-delay = <0x108>;
				regulator-default-on = <0x0>;
				status = "okay";
				linux,phandle = <0x43>;
				phandle = <0x43>;
			};

			ldo_vmc {
				regulator-name = "vmc";
				regulator-min-microvolt = <0x1b7740>;
				regulator-max-microvolt = <0x325aa0>;
				regulator-enable-ramp-delay = <0x2c>;
				regulator-default-on = <0x0>;
				status = "okay";
				linux,phandle = <0x6f>;
				phandle = <0x6f>;
			};

			ldo_vmch {
				regulator-name = "vmch";
				regulator-min-microvolt = <0x2dc6c0>;
				regulator-max-microvolt = <0x325aa0>;
				regulator-enable-ramp-delay = <0x2c>;
				regulator-default-on = <0x0>;
				status = "okay";
				linux,phandle = <0x70>;
				phandle = <0x70>;
			};

			ldo_vibr {
				regulator-name = "vibr";
				regulator-min-microvolt = <0x124f80>;
				regulator-max-microvolt = <0x325aa0>;
				regulator-enable-ramp-delay = <0x2c>;
				regulator-default-on = <0x0>;
				status = "okay";
				linux,phandle = <0x71>;
				phandle = <0x71>;
			};

			ldo_vrtc {
				regulator-name = "vrtc";
				regulator-min-microvolt = <0x2ab980>;
				regulator-max-microvolt = <0x2ab980>;
				regulator-enable-ramp-delay = <0x2c>;
				linux,phandle = <0x72>;
				phandle = <0x72>;
			};

			ldo_vm {
				regulator-name = "vm";
				regulator-min-microvolt = <0x124f80>;
				regulator-max-microvolt = <0x1b7740>;
				regulator-enable-ramp-delay = <0x108>;
				regulator-boot-on;
				regulator-default-on = <0x0>;
				status = "okay";
				linux,phandle = <0x73>;
				phandle = <0x73>;
			};

			ldo_vrf18 {
				regulator-name = "vrf18";
				regulator-min-microvolt = <0x1b7740>;
				regulator-max-microvolt = <0x1b7740>;
				regulator-enable-ramp-delay = <0xdc>;
				regulator-default-on = <0x0>;
				status = "okay";
				linux,phandle = <0x74>;
				phandle = <0x74>;
			};

			ldo_vio18 {
				regulator-name = "vio18";
				regulator-min-microvolt = <0x1b7740>;
				regulator-max-microvolt = <0x1b7740>;
				regulator-enable-ramp-delay = <0x108>;
				regulator-boot-on;
				linux,phandle = <0x75>;
				phandle = <0x75>;
			};

			ldo_vcamd {
				regulator-name = "vcamd";
				regulator-min-microvolt = <0x124f80>;
				regulator-max-microvolt = <0x1b7740>;
				regulator-enable-ramp-delay = <0x108>;
				regulator-default-on = <0x0>;
				status = "okay";
				linux,phandle = <0x42>;
				phandle = <0x42>;
			};

			ldo_vcamio {
				regulator-name = "vcamio";
				regulator-min-microvolt = <0x1b7740>;
				regulator-max-microvolt = <0x1b7740>;
				regulator-enable-ramp-delay = <0xdc>;
				linux,phandle = <0x76>;
				phandle = <0x76>;
			};

			ldo_vgp3 {
				regulator-name = "vgp3";
				regulator-min-microvolt = <0x124f80>;
				regulator-max-microvolt = <0x1b7740>;
				regulator-enable-ramp-delay = <0x108>;
				regulator-default-on = <0x0>;
				status = "okay";
				linux,phandle = <0x77>;
				phandle = <0x77>;
			};

			ldo_vcn_1v8 {
				regulator-name = "vcn_1v8";
				regulator-min-microvolt = <0x1b7740>;
				regulator-max-microvolt = <0x1b7740>;
				regulator-enable-ramp-delay = <0x2c>;
				regulator-default-on = <0x0>;
				status = "okay";
				linux,phandle = <0x2d>;
				phandle = <0x2d>;
			};

			vcanio_ldo_reg {
				regulator-name = "vcanio";
				regulator-default-on = <0x0>;
				status = "okay";
				linux,phandle = <0x44>;
				phandle = <0x44>;
			};

			vcn33_ldo_reg {
				regulator-name = "vcn33";
				regulator-default-on = <0x0>;
				status = "okay";
			};
		};

		regulators_supply {
			compatible = "mediatek,mt_pmic_regulator_supply";
			vcn28-supply = <0x2e>;
			vtcxo-supply = <0x67>;
			va-supply = <0x68>;
			vcn33_bt-supply = <0x2f>;
			vcn33_wifi-supply = <0x30>;
			vio28-supply = <0x69>;
			vsim1-supply = <0x6a>;
			vsim2-supply = <0x6b>;
			vusb-supply = <0x6c>;
			vgp1-supply = <0xe>;
			vgp2-supply = <0x6d>;
			vemc_3v3-supply = <0x6e>;
			vcamaf-supply = <0x43>;
			vmc-supply = <0x6f>;
			vmch-supply = <0x70>;
			vibr-supply = <0x71>;
			vrtc-supply = <0x72>;
			vm-supply = <0x73>;
			vrf18-supply = <0x74>;
			vio18-supply = <0x75>;
			vcamd-supply = <0x42>;
			vcamio-supply = <0x76>;
			vgp3-supply = <0x77>;
			vcn_1v8-supply = <0x2d>;
		};
	};

	rf_clock_buffer {
		compatible = "mediatek,rf_clock_buffer";
		#mediatek,clkbuf-quantity = <0x4>;
		#mediatek,clkbuf-config = <0x2 0x1 0x1 0x1>;
		mediatek,clkbuf-quantity = <0x4>;
		mediatek,clkbuf-config = <0x2 0x2 0x1 0x1>;
		status = "okay";
	};

	trusty {
		compatible = "android,trusty-smc-v1";
		ranges;
		#address-cells = <0x2>;
		#size-cells = <0x2>;

		irq {
			compatible = "android,trusty-irq-v1";
			ppi-interrupt-parent = <0x1>;
		};

		log {
			compatible = "android,trusty-log-v1";
		};

		virtio {
			compatible = "android,trusty-virtio-v1";
		};

		mtee {
			compatible = "mediatek,trusty-mtee-v1";
		};
	};

	led@0 {
		compatible = "mediatek,red";
		led_mode = <0x3>;
		data = <0x2>;
		pwm_config = <0x0 0x0 0x0 0x0 0x0>;
	};

	led@1 {
		compatible = "mediatek,green";
		led_mode = <0x3>;
		data = <0x2>;
		pwm_config = <0x0 0x0 0x0 0x0 0x0>;
	};

	led@2 {
		compatible = "mediatek,blue";
		led_mode = <0x3>;
		data = <0x2>;
		pwm_config = <0x0 0x0 0x0 0x0 0x0>;
	};

	led@3 {
		compatible = "mediatek,jogball-backlight";
		led_mode = <0x0>;
		data = <0x1>;
		pwm_config = <0x0 0x0 0x0 0x0 0x0>;
	};

	led@4 {
		compatible = "mediatek,keyboard-backlight";
		led_mode = <0x0>;
		data = <0x1>;
		pwm_config = <0x0 0x0 0x0 0x0 0x0>;
	};

	led@5 {
		compatible = "mediatek,button-backlight";
		led_mode = <0x3>;
		data = <0x1>;
		pwm_config = <0x0 0x0 0x0 0x0 0x0>;
	};

	led@6 {
		compatible = "mediatek,lcd-backlight";
		led_mode = <0x5>;
		data = <0x1>;
		pwm_config = <0x0 0x0 0x0 0x0 0x0>;
	};

	vibrator@0 {
		compatible = "mediatek,vibrator";
		vib_timer = <0x19>;
		vib_limit = <0x9>;
		vib_vol = <0x6>;
	};

	cust_accel@0 {
		compatible	= "mediatek,kxtj2_1009_new";
		i2c_num		= <2>;
		i2c_addr	= <0xe 0 0 0>;
		direction	= <0x0>;
		power_id	= <0xffff>;
		power_vol	= <0>;
		firlen		= <0>;
		is_batch_supported	= <0>;
	};
	cust_accel@1 {
		compatible = "mediatek,mxc400x";
		i2c_num 	= <0x2>;
		i2c_addr 	= <0x4c 0x0 0x0 0x0>;
		direction 	= <0x0>;
		power_id 	= <0xffff>;
		power_vol 	= <0x0>;
		firlen 		= <0x0>;
		is_batch_supported = <0x0>;
	};

	cust_alsps@0 {
		compatible = "mediatek,epl259x";
		i2c_num = <0x2>;
		i2c_addr = <0x49 0x0 0x0 0x0>;
		polling_mode_ps = <0x1>;
		polling_mode_als = <0x1>;
		power_id = <0xffff>;
		power_vol = <0x0>;
		als_level = <0x0 0x7d 0x13f 0x20d 0x443 0x9b0 0xbf2 0x13fb 0x218d 0x2a11 0x3239 0x458f 0x564b 0xffff 0xffff>;
		als_value = <0x0 0x85 0x12f 0x1f8 0x3ea 0x7d3 0xbbe 0x138b 0x1f42 0x2710 0x2ee0 0x3e80 0x4e20 0x4e20 0x4e20 0x4e20>;
		ps_threshold_high = <0x1a>;
		ps_threshold_low = <0x15>;
		is_batch_supported_ps = <0x0>;
		is_batch_supported_als = <0x0>;
		ps_integration_time = <0x24>;
	};

	cust_mag@0 {
		compatible = "mediatek,mmc3524x";
		i2c_num = <0x2>;
		i2c_addr = <0x30 0x0 0x0 0x0>;
		direction = <0x0>;
		power_id = <0xffff>;
		power_vol = <0x0>;
		is_batch_supported = <0x0>;
	};

	cust_gyro@0 {
		compatible = "mediatek,ITG1010";
		i2c_num = <0x2>;
		i2c_addr = <0x68 0x0 0x0 0x0>;
		direction = <0x0>;
		power_id = <0xffff>;
		power_vol = <0x0>;
		firlen = <0x0>;
		is_batch_supported = <0x0>;
	};
};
